VERSION ""

NS_ :

BS_:

BU_: BCU DGPS Debugger ECU InboardFloor_FL InboardFloor_FR InboardFloor_RL InboardFloor_RR SAMM_Mag_1 SuspensionNode_FL SuspensionNode_FR SuspensionNode_RL SuspensionNode_RR TCM TireTemp_FL TireTemp_FR TireTemp_RL TireTemp_RR

BO_ 2150629633 BCU_Debug_FD_to_Debugger: 64 BCU
 SG_ Debug : 0|64@1- (1,0) [0|0] "" Debugger

BO_ 2150629889 BCU_Ping_to_Debugger: 4 BCU
 SG_ Timestamp : 0|32@1+ (1,0) [0|4.29497e+09] "ms" Debugger

BO_ 2150629890 BCU_Ping_to_ECU: 4 BCU
 SG_ Timestamp : 0|32@1+ (1,0) [0|4.29497e+09] "ms" ECU

BO_ 2150632706 BCU_BCU_Cell_Data_1_to_ECU: 64 BCU
 SG_ Cell_0_Voltage : 0|8@1+ (0.01,2) [2|4.55] "Volts" ECU
 SG_ Cell_0_Temp : 8|8@1+ (0.25,0) [0|63.75] "Celsius" ECU
 SG_ Cell_1_Voltage : 16|8@1+ (0.01,2) [2|4.55] "Volts" ECU
 SG_ Cell_1_Temp : 24|8@1+ (0.25,0) [0|63.75] "Celsius" ECU
 SG_ Cell_2_Voltage : 32|8@1+ (0.01,2) [2|4.55] "Volts" ECU
 SG_ Cell_2_Temp : 40|8@1+ (0.25,0) [0|63.75] "Celsius" ECU
 SG_ Cell_3_Voltage : 48|8@1+ (0.01,2) [2|4.55] "Volts" ECU
 SG_ Cell_3_Temp : 56|8@1+ (0.25,0) [0|63.75] "Celsius" ECU
 SG_ Cell_4_Voltage : 64|8@1+ (0.01,2) [2|4.55] "Volts" ECU
 SG_ Cell_4_Temp : 72|8@1+ (0.25,0) [0|63.75] "Celsius" ECU
 SG_ Cell_5_Voltage : 80|8@1+ (0.01,2) [2|4.55] "Volts" ECU
 SG_ Cell_5_Temp : 88|8@1+ (0.25,0) [0|63.75] "Celsius" ECU
 SG_ Cell_6_Voltage : 96|8@1+ (0.01,2) [2|4.55] "Volts" ECU
 SG_ Cell_6_Temp : 104|8@1+ (0.25,0) [0|63.75] "Celsius" ECU
 SG_ Cell_7_Voltage : 112|8@1+ (0.01,2) [2|4.55] "Volts" ECU
 SG_ Cell_7_Temp : 120|8@1+ (0.25,0) [0|63.75] "Celsius" ECU
 SG_ Cell_8_Voltage : 128|8@1+ (0.01,2) [2|4.55] "Volts" ECU
 SG_ Cell_8_Temp : 136|8@1+ (0.25,0) [0|63.75] "Celsius" ECU
 SG_ Cell_9_Voltage : 144|8@1+ (0.01,2) [2|4.55] "Volts" ECU
 SG_ Cell_9_Temp : 152|8@1+ (0.25,0) [0|63.75] "Celsius" ECU
 SG_ Cell_10_Voltage : 160|8@1+ (0.01,2) [2|4.55] "Volts" ECU
 SG_ Cell_10_Temp : 168|8@1+ (0.25,0) [0|63.75] "Celsius" ECU
 SG_ Cell_11_Voltage : 176|8@1+ (0.01,2) [2|4.55] "Volts" ECU
 SG_ Cell_11_Temp : 184|8@1+ (0.25,0) [0|63.75] "Celsius" ECU
 SG_ Cell_12_Voltage : 192|8@1+ (0.01,2) [2|4.55] "Volts" ECU
 SG_ Cell_12_Temp : 200|8@1+ (0.25,0) [0|63.75] "Celsius" ECU
 SG_ Cell_13_Voltage : 208|8@1+ (0.01,2) [2|4.55] "Volts" ECU
 SG_ Cell_13_Temp : 216|8@1+ (0.25,0) [0|63.75] "Celsius" ECU
 SG_ Cell_14_Voltage : 224|8@1+ (0.01,2) [2|4.55] "Volts" ECU
 SG_ Cell_14_Temp : 232|8@1+ (0.25,0) [0|63.75] "Celsius" ECU
 SG_ Cell_15_Voltage : 240|8@1+ (0.01,2) [2|4.55] "Volts" ECU
 SG_ Cell_15_Temp : 248|8@1+ (0.25,0) [0|63.75] "Celsius" ECU
 SG_ Cell_16_Voltage : 256|8@1+ (0.01,2) [2|4.55] "Volts" ECU
 SG_ Cell_16_Temp : 264|8@1+ (0.25,0) [0|63.75] "Celsius" ECU
 SG_ Cell_17_Voltage : 272|8@1+ (0.01,2) [2|4.55] "Volts" ECU
 SG_ Cell_17_Temp : 280|8@1+ (0.25,0) [0|63.75] "Celsius" ECU
 SG_ Cell_18_Voltage : 288|8@1+ (0.01,2) [2|4.55] "Volts" ECU
 SG_ Cell_18_Temp : 296|8@1+ (0.25,0) [0|63.75] "Celsius" ECU
 SG_ Cell_19_Voltage : 304|8@1+ (0.01,2) [2|4.55] "Volts" ECU
 SG_ Cell_19_Temp : 312|8@1+ (0.25,0) [0|63.75] "Celsius" ECU
 SG_ Cell_20_Voltage : 320|8@1+ (0.01,2) [2|4.55] "Volts" ECU
 SG_ Cell_20_Temp : 328|8@1+ (0.25,0) [0|63.75] "Celsius" ECU
 SG_ Cell_21_Voltage : 336|8@1+ (0.01,2) [2|4.55] "Volts" ECU
 SG_ Cell_21_Temp : 344|8@1+ (0.25,0) [0|63.75] "Celsius" ECU
 SG_ Cell_22_Voltage : 352|8@1+ (0.01,2) [2|4.55] "Volts" ECU
 SG_ Cell_22_Temp : 360|8@1+ (0.25,0) [0|63.75] "Celsius" ECU
 SG_ Cell_23_Voltage : 368|8@1+ (0.01,2) [2|4.55] "Volts" ECU
 SG_ Cell_23_Temp : 376|8@1+ (0.25,0) [0|63.75] "Celsius" ECU
 SG_ Cell_24_Voltage : 384|8@1+ (0.01,2) [2|4.55] "Volts" ECU
 SG_ Cell_24_Temp : 392|8@1+ (0.25,0) [0|63.75] "Celsius" ECU
 SG_ Cell_25_Voltage : 400|8@1+ (0.01,2) [2|4.55] "Volts" ECU
 SG_ Cell_25_Temp : 408|8@1+ (0.25,0) [0|63.75] "Celsius" ECU
 SG_ Cell_26_Voltage : 416|8@1+ (0.01,2) [2|4.55] "Volts" ECU
 SG_ Cell_26_Temp : 424|8@1+ (0.25,0) [0|63.75] "Celsius" ECU
 SG_ Cell_27_Voltage : 432|8@1+ (0.01,2) [2|4.55] "Volts" ECU
 SG_ Cell_27_Temp : 440|8@1+ (0.25,0) [0|63.75] "Celsius" ECU
 SG_ Cell_28_Voltage : 448|8@1+ (0.01,2) [2|4.55] "Volts" ECU
 SG_ Cell_28_Temp : 456|8@1+ (0.25,0) [0|63.75] "Celsius" ECU
 SG_ Cell_29_Voltage : 464|8@1+ (0.01,2) [2|4.55] "Volts" ECU
 SG_ Cell_29_Temp : 472|8@1+ (0.25,0) [0|63.75] "Celsius" ECU
 SG_ Cell_30_Voltage : 480|8@1+ (0.01,2) [2|4.55] "Volts" ECU
 SG_ Cell_30_Temp : 488|8@1+ (0.25,0) [0|63.75] "Celsius" ECU
 SG_ Cell_31_Voltage : 496|8@1+ (0.01,2) [2|4.55] "Volts" ECU
 SG_ Cell_31_Temp : 504|8@1+ (0.25,0) [0|63.75] "Celsius" ECU

BO_ 2150632962 BCU_BCU_Cell_Data_2_to_ECU: 64 BCU
 SG_ Cell_32_Voltage : 0|8@1+ (0.01,2) [2|4.55] "Volts" ECU
 SG_ Cell_32_Temp : 8|8@1+ (0.25,0) [0|63.75] "Celsius" ECU
 SG_ Cell_33_Voltage : 16|8@1+ (0.01,2) [2|4.55] "Volts" ECU
 SG_ Cell_33_Temp : 24|8@1+ (0.25,0) [0|63.75] "Celsius" ECU
 SG_ Cell_34_Voltage : 32|8@1+ (0.01,2) [2|4.55] "Volts" ECU
 SG_ Cell_34_Temp : 40|8@1+ (0.25,0) [0|63.75] "Celsius" ECU
 SG_ Cell_35_Voltage : 48|8@1+ (0.01,2) [2|4.55] "Volts" ECU
 SG_ Cell_35_Temp : 56|8@1+ (0.25,0) [0|63.75] "Celsius" ECU
 SG_ Cell_36_Voltage : 64|8@1+ (0.01,2) [2|4.55] "Volts" ECU
 SG_ Cell_36_Temp : 72|8@1+ (0.25,0) [0|63.75] "Celsius" ECU
 SG_ Cell_37_Voltage : 80|8@1+ (0.01,2) [2|4.55] "Volts" ECU
 SG_ Cell_37_Temp : 88|8@1+ (0.25,0) [0|63.75] "Celsius" ECU
 SG_ Cell_38_Voltage : 96|8@1+ (0.01,2) [2|4.55] "Volts" ECU
 SG_ Cell_38_Temp : 104|8@1+ (0.25,0) [0|63.75] "Celsius" ECU
 SG_ Cell_39_Voltage : 112|8@1+ (0.01,2) [2|4.55] "Volts" ECU
 SG_ Cell_39_Temp : 120|8@1+ (0.25,0) [0|63.75] "Celsius" ECU
 SG_ Cell_40_Voltage : 128|8@1+ (0.01,2) [2|4.55] "Volts" ECU
 SG_ Cell_40_Temp : 136|8@1+ (0.25,0) [0|63.75] "Celsius" ECU
 SG_ Cell_41_Voltage : 144|8@1+ (0.01,2) [2|4.55] "Volts" ECU
 SG_ Cell_41_Temp : 152|8@1+ (0.25,0) [0|63.75] "Celsius" ECU
 SG_ Cell_42_Voltage : 160|8@1+ (0.01,2) [2|4.55] "Volts" ECU
 SG_ Cell_42_Temp : 168|8@1+ (0.25,0) [0|63.75] "Celsius" ECU
 SG_ Cell_43_Voltage : 176|8@1+ (0.01,2) [2|4.55] "Volts" ECU
 SG_ Cell_43_Temp : 184|8@1+ (0.25,0) [0|63.75] "Celsius" ECU
 SG_ Cell_44_Voltage : 192|8@1+ (0.01,2) [2|4.55] "Volts" ECU
 SG_ Cell_44_Temp : 200|8@1+ (0.25,0) [0|63.75] "Celsius" ECU
 SG_ Cell_45_Voltage : 208|8@1+ (0.01,2) [2|4.55] "Volts" ECU
 SG_ Cell_45_Temp : 216|8@1+ (0.25,0) [0|63.75] "Celsius" ECU
 SG_ Cell_46_Voltage : 224|8@1+ (0.01,2) [2|4.55] "Volts" ECU
 SG_ Cell_46_Temp : 232|8@1+ (0.25,0) [0|63.75] "Celsius" ECU
 SG_ Cell_47_Voltage : 240|8@1+ (0.01,2) [2|4.55] "Volts" ECU
 SG_ Cell_47_Temp : 248|8@1+ (0.25,0) [0|63.75] "Celsius" ECU
 SG_ Cell_48_Voltage : 256|8@1+ (0.01,2) [2|4.55] "Volts" ECU
 SG_ Cell_48_Temp : 264|8@1+ (0.25,0) [0|63.75] "Celsius" ECU
 SG_ Cell_49_Voltage : 272|8@1+ (0.01,2) [2|4.55] "Volts" ECU
 SG_ Cell_49_Temp : 280|8@1+ (0.25,0) [0|63.75] "Celsius" ECU
 SG_ Cell_50_Voltage : 288|8@1+ (0.01,2) [2|4.55] "Volts" ECU
 SG_ Cell_50_Temp : 296|8@1+ (0.25,0) [0|63.75] "Celsius" ECU
 SG_ Cell_51_Voltage : 304|8@1+ (0.01,2) [2|4.55] "Volts" ECU
 SG_ Cell_51_Temp : 312|8@1+ (0.25,0) [0|63.75] "Celsius" ECU
 SG_ Cell_52_Voltage : 320|8@1+ (0.01,2) [2|4.55] "Volts" ECU
 SG_ Cell_52_Temp : 328|8@1+ (0.25,0) [0|63.75] "Celsius" ECU
 SG_ Cell_53_Voltage : 336|8@1+ (0.01,2) [2|4.55] "Volts" ECU
 SG_ Cell_53_Temp : 344|8@1+ (0.25,0) [0|63.75] "Celsius" ECU
 SG_ Cell_54_Voltage : 352|8@1+ (0.01,2) [2|4.55] "Volts" ECU
 SG_ Cell_54_Temp : 360|8@1+ (0.25,0) [0|63.75] "Celsius" ECU
 SG_ Cell_55_Voltage : 368|8@1+ (0.01,2) [2|4.55] "Volts" ECU
 SG_ Cell_55_Temp : 376|8@1+ (0.25,0) [0|63.75] "Celsius" ECU
 SG_ Cell_56_Voltage : 384|8@1+ (0.01,2) [2|4.55] "Volts" ECU
 SG_ Cell_56_Temp : 392|8@1+ (0.25,0) [0|63.75] "Celsius" ECU
 SG_ Cell_57_Voltage : 400|8@1+ (0.01,2) [2|4.55] "Volts" ECU
 SG_ Cell_57_Temp : 408|8@1+ (0.25,0) [0|63.75] "Celsius" ECU
 SG_ Cell_58_Voltage : 416|8@1+ (0.01,2) [2|4.55] "Volts" ECU
 SG_ Cell_58_Temp : 424|8@1+ (0.25,0) [0|63.75] "Celsius" ECU
 SG_ Cell_59_Voltage : 432|8@1+ (0.01,2) [2|4.55] "Volts" ECU
 SG_ Cell_59_Temp : 440|8@1+ (0.25,0) [0|63.75] "Celsius" ECU
 SG_ Cell_60_Voltage : 448|8@1+ (0.01,2) [2|4.55] "Volts" ECU
 SG_ Cell_60_Temp : 456|8@1+ (0.25,0) [0|63.75] "Celsius" ECU
 SG_ Cell_61_Voltage : 464|8@1+ (0.01,2) [2|4.55] "Volts" ECU
 SG_ Cell_61_Temp : 472|8@1+ (0.25,0) [0|63.75] "Celsius" ECU
 SG_ Cell_62_Voltage : 480|8@1+ (0.01,2) [2|4.55] "Volts" ECU
 SG_ Cell_62_Temp : 488|8@1+ (0.25,0) [0|63.75] "Celsius" ECU
 SG_ Cell_63_Voltage : 496|8@1+ (0.01,2) [2|4.55] "Volts" ECU
 SG_ Cell_63_Temp : 504|8@1+ (0.25,0) [0|63.75] "Celsius" ECU

BO_ 2150633218 BCU_BCU_Cell_Data_3_to_ECU: 64 BCU
 SG_ Cell_64_Voltage : 0|8@1+ (0.01,2) [2|4.55] "Volts" ECU
 SG_ Cell_64_Temp : 8|8@1+ (0.25,0) [0|63.75] "Celsius" ECU
 SG_ Cell_65_Voltage : 16|8@1+ (0.01,2) [2|4.55] "Volts" ECU
 SG_ Cell_65_Temp : 24|8@1+ (0.25,0) [0|63.75] "Celsius" ECU
 SG_ Cell_66_Voltage : 32|8@1+ (0.01,2) [2|4.55] "Volts" ECU
 SG_ Cell_66_Temp : 40|8@1+ (0.25,0) [0|63.75] "Celsius" ECU
 SG_ Cell_67_Voltage : 48|8@1+ (0.01,2) [2|4.55] "Volts" ECU
 SG_ Cell_67_Temp : 56|8@1+ (0.25,0) [0|63.75] "Celsius" ECU
 SG_ Cell_68_Voltage : 64|8@1+ (0.01,2) [2|4.55] "Volts" ECU
 SG_ Cell_68_Temp : 72|8@1+ (0.25,0) [0|63.75] "Celsius" ECU
 SG_ Cell_69_Voltage : 80|8@1+ (0.01,2) [2|4.55] "Volts" ECU
 SG_ Cell_69_Temp : 88|8@1+ (0.25,0) [0|63.75] "Celsius" ECU
 SG_ Cell_70_Voltage : 96|8@1+ (0.01,2) [2|4.55] "Volts" ECU
 SG_ Cell_70_Temp : 104|8@1+ (0.25,0) [0|63.75] "Celsius" ECU
 SG_ Cell_71_Voltage : 112|8@1+ (0.01,2) [2|4.55] "Volts" ECU
 SG_ Cell_71_Temp : 120|8@1+ (0.25,0) [0|63.75] "Celsius" ECU
 SG_ Cell_72_Voltage : 128|8@1+ (0.01,2) [2|4.55] "Volts" ECU
 SG_ Cell_72_Temp : 136|8@1+ (0.25,0) [0|63.75] "Celsius" ECU
 SG_ Cell_73_Voltage : 144|8@1+ (0.01,2) [2|4.55] "Volts" ECU
 SG_ Cell_73_Temp : 152|8@1+ (0.25,0) [0|63.75] "Celsius" ECU
 SG_ Cell_74_Voltage : 160|8@1+ (0.01,2) [2|4.55] "Volts" ECU
 SG_ Cell_74_Temp : 168|8@1+ (0.25,0) [0|63.75] "Celsius" ECU
 SG_ Cell_75_Voltage : 176|8@1+ (0.01,2) [2|4.55] "Volts" ECU
 SG_ Cell_75_Temp : 184|8@1+ (0.25,0) [0|63.75] "Celsius" ECU
 SG_ Cell_76_Voltage : 192|8@1+ (0.01,2) [2|4.55] "Volts" ECU
 SG_ Cell_76_Temp : 200|8@1+ (0.25,0) [0|63.75] "Celsius" ECU
 SG_ Cell_77_Voltage : 208|8@1+ (0.01,2) [2|4.55] "Volts" ECU
 SG_ Cell_77_Temp : 216|8@1+ (0.25,0) [0|63.75] "Celsius" ECU
 SG_ Cell_78_Voltage : 224|8@1+ (0.01,2) [2|4.55] "Volts" ECU
 SG_ Cell_78_Temp : 232|8@1+ (0.25,0) [0|63.75] "Celsius" ECU
 SG_ Cell_79_Voltage : 240|8@1+ (0.01,2) [2|4.55] "Volts" ECU
 SG_ Cell_79_Temp : 248|8@1+ (0.25,0) [0|63.75] "Celsius" ECU
 SG_ Cell_80_Voltage : 256|8@1+ (0.01,2) [2|4.55] "Volts" ECU
 SG_ Cell_80_Temp : 264|8@1+ (0.25,0) [0|63.75] "Celsius" ECU
 SG_ Cell_81_Voltage : 272|8@1+ (0.01,2) [2|4.55] "Volts" ECU
 SG_ Cell_81_Temp : 280|8@1+ (0.25,0) [0|63.75] "Celsius" ECU
 SG_ Cell_82_Voltage : 288|8@1+ (0.01,2) [2|4.55] "Volts" ECU
 SG_ Cell_82_Temp : 296|8@1+ (0.25,0) [0|63.75] "Celsius" ECU
 SG_ Cell_83_Voltage : 304|8@1+ (0.01,2) [2|4.55] "Volts" ECU
 SG_ Cell_83_Temp : 312|8@1+ (0.25,0) [0|63.75] "Celsius" ECU
 SG_ Cell_84_Voltage : 320|8@1+ (0.01,2) [2|4.55] "Volts" ECU
 SG_ Cell_84_Temp : 328|8@1+ (0.25,0) [0|63.75] "Celsius" ECU
 SG_ Cell_85_Voltage : 336|8@1+ (0.01,2) [2|4.55] "Volts" ECU
 SG_ Cell_85_Temp : 344|8@1+ (0.25,0) [0|63.75] "Celsius" ECU
 SG_ Cell_86_Voltage : 352|8@1+ (0.01,2) [2|4.55] "Volts" ECU
 SG_ Cell_86_Temp : 360|8@1+ (0.25,0) [0|63.75] "Celsius" ECU
 SG_ Cell_87_Voltage : 368|8@1+ (0.01,2) [2|4.55] "Volts" ECU
 SG_ Cell_87_Temp : 376|8@1+ (0.25,0) [0|63.75] "Celsius" ECU
 SG_ Cell_88_Voltage : 384|8@1+ (0.01,2) [2|4.55] "Volts" ECU
 SG_ Cell_88_Temp : 392|8@1+ (0.25,0) [0|63.75] "Celsius" ECU
 SG_ Cell_89_Voltage : 400|8@1+ (0.01,2) [2|4.55] "Volts" ECU
 SG_ Cell_89_Temp : 408|8@1+ (0.25,0) [0|63.75] "Celsius" ECU
 SG_ Cell_90_Voltage : 416|8@1+ (0.01,2) [2|4.55] "Volts" ECU
 SG_ Cell_90_Temp : 424|8@1+ (0.25,0) [0|63.75] "Celsius" ECU
 SG_ Cell_91_Voltage : 432|8@1+ (0.01,2) [2|4.55] "Volts" ECU
 SG_ Cell_91_Temp : 440|8@1+ (0.25,0) [0|63.75] "Celsius" ECU
 SG_ Cell_92_Voltage : 448|8@1+ (0.01,2) [2|4.55] "Volts" ECU
 SG_ Cell_92_Temp : 456|8@1+ (0.25,0) [0|63.75] "Celsius" ECU
 SG_ Cell_93_Voltage : 464|8@1+ (0.01,2) [2|4.55] "Volts" ECU
 SG_ Cell_93_Temp : 472|8@1+ (0.25,0) [0|63.75] "Celsius" ECU
 SG_ Cell_94_Voltage : 480|8@1+ (0.01,2) [2|4.55] "Volts" ECU
 SG_ Cell_94_Temp : 488|8@1+ (0.25,0) [0|63.75] "Celsius" ECU
 SG_ Cell_95_Voltage : 496|8@1+ (0.01,2) [2|4.55] "Volts" ECU
 SG_ Cell_95_Temp : 504|8@1+ (0.25,0) [0|63.75] "Celsius" ECU

BO_ 2150633474 BCU_BCU_Cell_Data_4_to_ECU: 64 BCU
 SG_ Cell_96_Voltage : 0|8@1+ (0.01,2) [2|4.55] "Volts" ECU
 SG_ Cell_96_Temp : 8|8@1+ (0.25,0) [0|63.75] "Celsius" ECU
 SG_ Cell_97_Voltage : 16|8@1+ (0.01,2) [2|4.55] "Volts" ECU
 SG_ Cell_97_Temp : 24|8@1+ (0.25,0) [0|63.75] "Celsius" ECU
 SG_ Cell_98_Voltage : 32|8@1+ (0.01,2) [2|4.55] "Volts" ECU
 SG_ Cell_98_Temp : 40|8@1+ (0.25,0) [0|63.75] "Celsius" ECU
 SG_ Cell_99_Voltage : 48|8@1+ (0.01,2) [2|4.55] "Volts" ECU
 SG_ Cell_99_Temp : 56|8@1+ (0.25,0) [0|63.75] "Celsius" ECU
 SG_ Cell_100_Voltage : 64|8@1+ (0.01,2) [2|4.55] "Volts" ECU
 SG_ Cell_100_Temp : 72|8@1+ (0.25,0) [0|63.75] "Celsius" ECU
 SG_ Cell_101_Voltage : 80|8@1+ (0.01,2) [2|4.55] "Volts" ECU
 SG_ Cell_101_Temp : 88|8@1+ (0.25,0) [0|63.75] "Celsius" ECU
 SG_ Cell_102_Voltage : 96|8@1+ (0.01,2) [2|4.55] "Volts" ECU
 SG_ Cell_102_Temp : 104|8@1+ (0.25,0) [0|63.75] "Celsius" ECU
 SG_ Cell_103_Voltage : 112|8@1+ (0.01,2) [2|4.55] "Volts" ECU
 SG_ Cell_103_Temp : 120|8@1+ (0.25,0) [0|63.75] "Celsius" ECU
 SG_ Cell_104_Voltage : 128|8@1+ (0.01,2) [2|4.55] "Volts" ECU
 SG_ Cell_104_Temp : 136|8@1+ (0.25,0) [0|63.75] "Celsius" ECU
 SG_ Cell_105_Voltage : 144|8@1+ (0.01,2) [2|4.55] "Volts" ECU
 SG_ Cell_105_Temp : 152|8@1+ (0.25,0) [0|63.75] "Celsius" ECU
 SG_ Cell_106_Voltage : 160|8@1+ (0.01,2) [2|4.55] "Volts" ECU
 SG_ Cell_106_Temp : 168|8@1+ (0.25,0) [0|63.75] "Celsius" ECU
 SG_ Cell_107_Voltage : 176|8@1+ (0.01,2) [2|4.55] "Volts" ECU
 SG_ Cell_107_Temp : 184|8@1+ (0.25,0) [0|63.75] "Celsius" ECU
 SG_ Cell_108_Voltage : 192|8@1+ (0.01,2) [2|4.55] "Volts" ECU
 SG_ Cell_108_Temp : 200|8@1+ (0.25,0) [0|63.75] "Celsius" ECU
 SG_ Cell_109_Voltage : 208|8@1+ (0.01,2) [2|4.55] "Volts" ECU
 SG_ Cell_109_Temp : 216|8@1+ (0.25,0) [0|63.75] "Celsius" ECU
 SG_ Cell_110_Voltage : 224|8@1+ (0.01,2) [2|4.55] "Volts" ECU
 SG_ Cell_110_Temp : 232|8@1+ (0.25,0) [0|63.75] "Celsius" ECU
 SG_ Cell_111_Voltage : 240|8@1+ (0.01,2) [2|4.55] "Volts" ECU
 SG_ Cell_111_Temp : 248|8@1+ (0.25,0) [0|63.75] "Celsius" ECU
 SG_ Cell_112_Voltage : 256|8@1+ (0.01,2) [2|4.55] "Volts" ECU
 SG_ Cell_112_Temp : 264|8@1+ (0.25,0) [0|63.75] "Celsius" ECU
 SG_ Cell_113_Voltage : 272|8@1+ (0.01,2) [2|4.55] "Volts" ECU
 SG_ Cell_113_Temp : 280|8@1+ (0.25,0) [0|63.75] "Celsius" ECU
 SG_ Cell_114_Voltage : 288|8@1+ (0.01,2) [2|4.55] "Volts" ECU
 SG_ Cell_114_Temp : 296|8@1+ (0.25,0) [0|63.75] "Celsius" ECU
 SG_ Cell_115_Voltage : 304|8@1+ (0.01,2) [2|4.55] "Volts" ECU
 SG_ Cell_115_Temp : 312|8@1+ (0.25,0) [0|63.75] "Celsius" ECU
 SG_ Cell_116_Voltage : 320|8@1+ (0.01,2) [2|4.55] "Volts" ECU
 SG_ Cell_116_Temp : 328|8@1+ (0.25,0) [0|63.75] "Celsius" ECU
 SG_ Cell_117_Voltage : 336|8@1+ (0.01,2) [2|4.55] "Volts" ECU
 SG_ Cell_117_Temp : 344|8@1+ (0.25,0) [0|63.75] "Celsius" ECU
 SG_ Cell_118_Voltage : 352|8@1+ (0.01,2) [2|4.55] "Volts" ECU
 SG_ Cell_118_Temp : 360|8@1+ (0.25,0) [0|63.75] "Celsius" ECU
 SG_ Cell_119_Voltage : 368|8@1+ (0.01,2) [2|4.55] "Volts" ECU
 SG_ Cell_119_Temp : 376|8@1+ (0.25,0) [0|63.75] "Celsius" ECU
 SG_ Cell_120_Voltage : 384|8@1+ (0.01,2) [2|4.55] "Volts" ECU
 SG_ Cell_120_Temp : 392|8@1+ (0.25,0) [0|63.75] "Celsius" ECU
 SG_ Cell_121_Voltage : 400|8@1+ (0.01,2) [2|4.55] "Volts" ECU
 SG_ Cell_121_Temp : 408|8@1+ (0.25,0) [0|63.75] "Celsius" ECU
 SG_ Cell_122_Voltage : 416|8@1+ (0.01,2) [2|4.55] "Volts" ECU
 SG_ Cell_122_Temp : 424|8@1+ (0.25,0) [0|63.75] "Celsius" ECU
 SG_ Cell_123_Voltage : 432|8@1+ (0.01,2) [2|4.55] "Volts" ECU
 SG_ Cell_123_Temp : 440|8@1+ (0.25,0) [0|63.75] "Celsius" ECU
 SG_ Cell_124_Voltage : 448|8@1+ (0.01,2) [2|4.55] "Volts" ECU
 SG_ Cell_124_Temp : 456|8@1+ (0.25,0) [0|63.75] "Celsius" ECU
 SG_ Cell_125_Voltage : 464|8@1+ (0.01,2) [2|4.55] "Volts" ECU
 SG_ Cell_125_Temp : 472|8@1+ (0.25,0) [0|63.75] "Celsius" ECU
 SG_ Cell_126_Voltage : 480|8@1+ (0.01,2) [2|4.55] "Volts" ECU
 SG_ Cell_126_Temp : 488|8@1+ (0.25,0) [0|63.75] "Celsius" ECU
 SG_ Cell_127_Voltage : 496|8@1+ (0.01,2) [2|4.55] "Volts" ECU
 SG_ Cell_127_Temp : 504|8@1+ (0.25,0) [0|63.75] "Celsius" ECU

BO_ 2150633730 BCU_BCU_Cell_Data_5_to_ECU: 64 BCU
 SG_ Cell_128_Voltage : 0|8@1+ (0.01,2) [2|4.55] "Volts" ECU
 SG_ Cell_128_Temp : 8|8@1+ (0.25,0) [0|63.75] "Celsius" ECU
 SG_ Cell_129_Voltage : 16|8@1+ (0.01,2) [2|4.55] "Volts" ECU
 SG_ Cell_129_Temp : 24|8@1+ (0.25,0) [0|63.75] "Celsius" ECU
 SG_ Cell_130_Voltage : 32|8@1+ (0.01,2) [2|4.55] "Volts" ECU
 SG_ Cell_130_Temp : 40|8@1+ (0.25,0) [0|63.75] "Celsius" ECU
 SG_ Cell_131_Voltage : 48|8@1+ (0.01,2) [2|4.55] "Volts" ECU
 SG_ Cell_131_Temp : 56|8@1+ (0.25,0) [0|63.75] "Celsius" ECU
 SG_ Cell_132_Voltage : 64|8@1+ (0.01,2) [2|4.55] "Volts" ECU
 SG_ Cell_132_Temp : 72|8@1+ (0.25,0) [0|63.75] "Celsius" ECU
 SG_ Cell_133_Voltage : 80|8@1+ (0.01,2) [2|4.55] "Volts" ECU
 SG_ Cell_133_Temp : 88|8@1+ (0.25,0) [0|63.75] "Celsius" ECU
 SG_ Cell_134_Voltage : 96|8@1+ (0.01,2) [2|4.55] "Volts" ECU
 SG_ Cell_134_Temp : 104|8@1+ (0.25,0) [0|63.75] "Celsius" ECU
 SG_ Cell_135_Voltage : 112|8@1+ (0.01,2) [2|4.55] "Volts" ECU
 SG_ Cell_135_Temp : 120|8@1+ (0.25,0) [0|63.75] "Celsius" ECU
 SG_ Cell_136_Voltage : 128|8@1+ (0.01,2) [2|4.55] "Volts" ECU
 SG_ Cell_136_Temp : 136|8@1+ (0.25,0) [0|63.75] "Celsius" ECU
 SG_ Cell_137_Voltage : 144|8@1+ (0.01,2) [2|4.55] "Volts" ECU
 SG_ Cell_137_Temp : 152|8@1+ (0.25,0) [0|63.75] "Celsius" ECU
 SG_ Cell_138_Voltage : 160|8@1+ (0.01,2) [2|4.55] "Volts" ECU
 SG_ Cell_138_Temp : 168|8@1+ (0.25,0) [0|63.75] "Celsius" ECU
 SG_ Cell_139_Voltage : 176|8@1+ (0.01,2) [2|4.55] "Volts" ECU
 SG_ Cell_139_Temp : 184|8@1+ (0.25,0) [0|63.75] "Celsius" ECU
 SG_ Cell_140_Voltage : 192|8@1+ (0.01,2) [2|4.55] "Volts" ECU
 SG_ Cell_140_Temp : 200|8@1+ (0.25,0) [0|63.75] "Celsius" ECU
 SG_ Cell_141_Voltage : 208|8@1+ (0.01,2) [2|4.55] "Volts" ECU
 SG_ Cell_141_Temp : 216|8@1+ (0.25,0) [0|63.75] "Celsius" ECU
 SG_ Cell_142_Voltage : 224|8@1+ (0.01,2) [2|4.55] "Volts" ECU
 SG_ Cell_142_Temp : 232|8@1+ (0.25,0) [0|63.75] "Celsius" ECU
 SG_ Cell_143_Voltage : 240|8@1+ (0.01,2) [2|4.55] "Volts" ECU
 SG_ Cell_143_Temp : 248|8@1+ (0.25,0) [0|63.75] "Celsius" ECU
 SG_ Cell_144_Voltage : 256|8@1+ (0.01,2) [2|4.55] "Volts" ECU
 SG_ Cell_144_Temp : 264|8@1+ (0.25,0) [0|63.75] "Celsius" ECU
 SG_ Cell_145_Voltage : 272|8@1+ (0.01,2) [2|4.55] "Volts" ECU
 SG_ Cell_145_Temp : 280|8@1+ (0.25,0) [0|63.75] "Celsius" ECU
 SG_ Cell_146_Voltage : 288|8@1+ (0.01,2) [2|4.55] "Volts" ECU
 SG_ Cell_146_Temp : 296|8@1+ (0.25,0) [0|63.75] "Celsius" ECU
 SG_ Cell_147_Voltage : 304|8@1+ (0.01,2) [2|4.55] "Volts" ECU
 SG_ Cell_147_Temp : 312|8@1+ (0.25,0) [0|63.75] "Celsius" ECU
 SG_ Cell_148_Voltage : 320|8@1+ (0.01,2) [2|4.55] "Volts" ECU
 SG_ Cell_148_Temp : 328|8@1+ (0.25,0) [0|63.75] "Celsius" ECU
 SG_ Cell_149_Voltage : 336|8@1+ (0.01,2) [2|4.55] "Volts" ECU
 SG_ Cell_149_Temp : 344|8@1+ (0.25,0) [0|63.75] "Celsius" ECU
 SG_ Cell_150_Voltage : 352|8@1+ (0.01,2) [2|4.55] "Volts" ECU
 SG_ Cell_150_Temp : 360|8@1+ (0.25,0) [0|63.75] "Celsius" ECU
 SG_ Cell_151_Voltage : 368|8@1+ (0.01,2) [2|4.55] "Volts" ECU
 SG_ Cell_151_Temp : 376|8@1+ (0.25,0) [0|63.75] "Celsius" ECU
 SG_ Cell_152_Voltage : 384|8@1+ (0.01,2) [2|4.55] "Volts" ECU
 SG_ Cell_152_Temp : 392|8@1+ (0.25,0) [0|63.75] "Celsius" ECU
 SG_ Cell_153_Voltage : 400|8@1+ (0.01,2) [2|4.55] "Volts" ECU
 SG_ Cell_153_Temp : 408|8@1+ (0.25,0) [0|63.75] "Celsius" ECU
 SG_ Cell_154_Voltage : 416|8@1+ (0.01,2) [2|4.55] "Volts" ECU
 SG_ Cell_154_Temp : 424|8@1+ (0.25,0) [0|63.75] "Celsius" ECU
 SG_ Cell_155_Voltage : 432|8@1+ (0.01,2) [2|4.55] "Volts" ECU
 SG_ Cell_155_Temp : 440|8@1+ (0.25,0) [0|63.75] "Celsius" ECU
 SG_ Cell_156_Voltage : 448|8@1+ (0.01,2) [2|4.55] "Volts" ECU
 SG_ Cell_156_Temp : 456|8@1+ (0.25,0) [0|63.75] "Celsius" ECU
 SG_ Cell_157_Voltage : 464|8@1+ (0.01,2) [2|4.55] "Volts" ECU
 SG_ Cell_157_Temp : 472|8@1+ (0.25,0) [0|63.75] "Celsius" ECU
 SG_ Cell_158_Voltage : 480|8@1+ (0.01,2) [2|4.55] "Volts" ECU
 SG_ Cell_158_Temp : 488|8@1+ (0.25,0) [0|63.75] "Celsius" ECU
 SG_ Cell_159_Voltage : 496|8@1+ (0.01,2) [2|4.55] "Volts" ECU
 SG_ Cell_159_Temp : 504|8@1+ (0.25,0) [0|63.75] "Celsius" ECU

BO_ 2148532482 Debugger_Debug_FD_to_ECU: 64 Debugger
 SG_ Debug : 0|64@1- (1,0) [0|0] "" ECU

BO_ 2148532738 Debugger_Ping_to_ECU: 4 Debugger
 SG_ Timestamp : 0|32@1+ (1,0) [0|4.29497e+09] "ms" ECU

BO_ 2148532483 Debugger_Debug_FD_to_BCU: 64 Debugger
 SG_ Debug : 0|64@1- (1,0) [0|0] "" BCU

BO_ 2148532739 Debugger_Ping_to_BCU: 4 Debugger
 SG_ Timestamp : 0|32@1+ (1,0) [0|4.29497e+09] "ms" BCU

BO_ 2148532484 Debugger_Debug_FD_to_TCM: 64 Debugger
 SG_ Debug : 0|64@1- (1,0) [0|0] "" TCM

BO_ 2148532740 Debugger_Ping_to_TCM: 4 Debugger
 SG_ Timestamp : 0|32@1+ (1,0) [0|4.29497e+09] "ms" TCM

BO_ 2149581057 ECU_Debug_FD_to_Debugger: 64 ECU
 SG_ Debug : 0|64@1- (1,0) [0|0] "" Debugger

BO_ 2149581313 ECU_Ping_to_Debugger: 4 ECU
 SG_ Timestamp : 0|32@1+ (1,0) [0|4.29497e+09] "ms" Debugger

BO_ 2149592580 ECU_ECU_Analog_Data_to_TCM: 16 ECU
 SG_ BSPD_Signal : 0|16@1+ (0.0015259,0) [0|100] "%" TCM
 SG_ BSE_Signal : 16|16@1+ (0.0015259,0) [0|100] "%" TCM
 SG_ APPS_1_Signal : 32|16@1+ (0.0015259,0) [0|100] "%" TCM
 SG_ APPS_2_Signal : 48|16@1+ (0.0015259,0) [0|100] "%" TCM
 SG_ Brakeline_F_Signal : 64|16@1+ (0.0015259,0) [0|100] "%" TCM
 SG_ Brakeline_R_Signal : 80|16@1+ (0.0015259,0) [0|100] "%" TCM
 SG_ Steering_Angle_Signal : 96|16@1+ (0.0015259,0) [0|100] "%" TCM
 SG_ AUX_Signal : 112|16@1+ (0.0015259,0) [0|100] "%" TCM

BO_ 2149592836 ECU_ECU_Performance_to_TCM: 4 ECU
 SG_ Elapsed_Cycles : 0|32@1+ (1,0) [0|0] "Clock Cycles" TCM

BO_ 2147615264 ECU_Ping_to_InboardFloor_FL: 4 ECU
 SG_ Timestamp : 0|32@1+ (1,0) [0|4.29497e+09] "ms" InboardFloor_FL

BO_ 2147615265 ECU_Ping_to_InboardFloor_FR: 4 ECU
 SG_ Timestamp : 0|32@1+ (1,0) [0|4.29497e+09] "ms" InboardFloor_FR

BO_ 2147615266 ECU_Ping_to_InboardFloor_RL: 4 ECU
 SG_ Timestamp : 0|32@1+ (1,0) [0|4.29497e+09] "ms" InboardFloor_RL

BO_ 2147615267 ECU_Ping_to_InboardFloor_RR: 4 ECU
 SG_ Timestamp : 0|32@1+ (1,0) [0|4.29497e+09] "ms" InboardFloor_RR

BO_ 2147615268 ECU_Ping_to_SuspensionNode_FL: 4 ECU
 SG_ Timestamp : 0|32@1+ (1,0) [0|4.29497e+09] "ms" SuspensionNode_FL

BO_ 2147615269 ECU_Ping_to_SuspensionNode_FR: 4 ECU
 SG_ Timestamp : 0|32@1+ (1,0) [0|4.29497e+09] "ms" SuspensionNode_FR

BO_ 2147615270 ECU_Ping_to_SuspensionNode_RL: 4 ECU
 SG_ Timestamp : 0|32@1+ (1,0) [0|4.29497e+09] "ms" SuspensionNode_RL

BO_ 2147615271 ECU_Ping_to_SuspensionNode_RR: 4 ECU
 SG_ Timestamp : 0|32@1+ (1,0) [0|4.29497e+09] "ms" SuspensionNode_RR

BO_ 2151678465 TCM_Ping_to_Debugger: 4 TCM
 SG_ Timestamp : 0|32@1+ (1,0) [0|4.29497e+09] "ms" Debugger

BO_ 2197828356 DGPS_GPS_ALT_to_TCM: 8 DGPS
 SG_ ALT : 0|64@1+ (1,0) [0|0] "" TCM

BO_ 2197827844 DGPS_GPS_LAT_to_TCM: 8 DGPS
 SG_ LAT : 0|64@1+ (1,0) [0|0] "" TCM

BO_ 2197828100 DGPS_GPS_LON_to_TCM: 8 DGPS
 SG_ LON : 0|64@1+ (1,0) [0|0] "" TCM

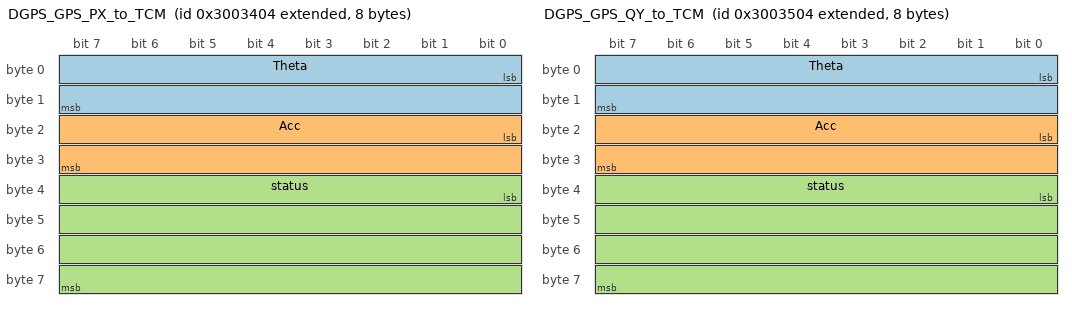
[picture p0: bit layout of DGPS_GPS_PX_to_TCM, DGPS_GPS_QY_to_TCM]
BO_ 2197828612 DGPS_GPS_PX_to_TCM: 8 DGPS
 SG_ Theta : 0|16@1- (0.001,0) [0|0] "" TCM
 SG_ Acc : 16|16@1- (0.01,0) [0|0] "" TCM
 SG_ status : 32|32@1+ (1,0) [0|0] "" TCM

BO_ 2197828868 DGPS_GPS_QY_to_TCM: 8 DGPS
 SG_ Theta : 0|16@1- (0.001,0) [0|0] "" TCM
 SG_ Acc : 16|16@1- (0.01,0) [0|0] "" TCM
 SG_ status : 32|32@1+ (1,0) [0|0] "" TCM

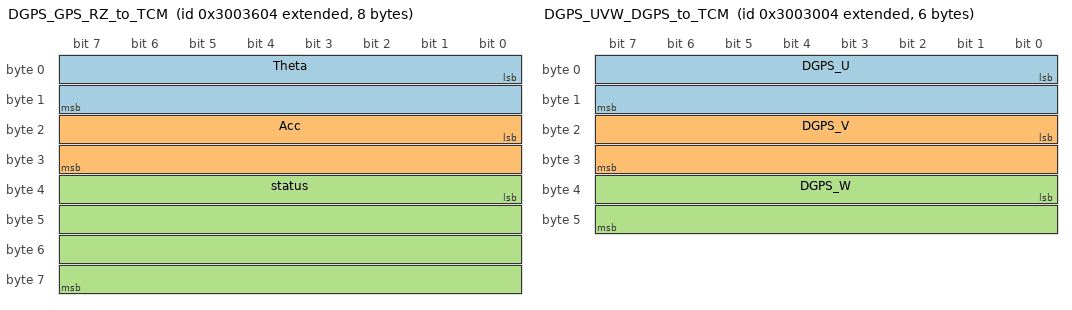
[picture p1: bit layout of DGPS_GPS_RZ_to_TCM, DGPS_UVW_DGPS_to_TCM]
BO_ 2197829124 DGPS_GPS_RZ_to_TCM: 8 DGPS
 SG_ Theta : 0|16@1- (0.001,0) [0|0] "" TCM
 SG_ Acc : 16|16@1- (0.01,0) [0|0] "" TCM
 SG_ status : 32|32@1+ (1,0) [0|0] "" TCM

BO_ 2197827588 DGPS_UVW_DGPS_to_TCM: 6 DGPS
 SG_ DGPS_U : 0|16@1- (0.01,0) [0|0] "" TCM
 SG_ DGPS_V : 16|16@1- (0.01,0) [0|0] "" TCM
 SG_ DGPS_W : 32|16@1- (0.01,0) [0|0] "" TCM

BO_ 514 SAMM_Mag_1_Ping_to_ECU: 4 SAMM_Mag_1
 SG_ Timestamp : 0|32@1+ (1,0) [0|4.29497e+09] "ms" ECU

BO_ 2150105602 TireTemp_FL_Ping_to_ECU: 4 TireTemp_FL
 SG_ Timestamp : 0|32@1+ (1,0) [0|4.29497e+09] "ms" ECU

BO_ 2150171138 TireTemp_FR_Ping_to_ECU: 4 TireTemp_FR
 SG_ Timestamp : 0|32@1+ (1,0) [0|4.29497e+09] "ms" ECU

BO_ 2150236674 TireTemp_RL_Ping_to_ECU: 4 TireTemp_RL
 SG_ Timestamp : 0|32@1+ (1,0) [0|4.29497e+09] "ms" ECU

BO_ 2150302210 TireTemp_RR_Ping_to_ECU: 4 TireTemp_RR
 SG_ Timestamp : 0|32@1+ (1,0) [0|4.29497e+09] "ms" ECU

CM_ SG_ 2147680513 Debug "Essentially a print statement up to 64 bytes long that whichever targeted can parse";
CM_ SG_ 2147680769 Timestamp "Time in millis";
CM_ SG_ 2147680770 Timestamp "Time in millis";
CM_ SG_ 2147683586 Cell_0_Voltage "Cell  n voltage";
CM_ SG_ 2147683586 Cell_0_Temp "Cell n temperature";
CM_ SG_ 2147683586 Cell_1_Voltage "Cell  n voltage";
CM_ SG_ 2147683586 Cell_1_Temp "Cell n temperature";
CM_ SG_ 2147683586 Cell_2_Voltage "Cell  n voltage";
CM_ SG_ 2147683586 Cell_2_Temp "Cell n temperature";
CM_ SG_ 2147683586 Cell_3_Voltage "Cell  n voltage";
CM_ SG_ 2147683586 Cell_3_Temp "Cell n temperature";
CM_ SG_ 2147683586 Cell_4_Voltage "Cell  n voltage";
CM_ SG_ 2147683586 Cell_4_Temp "Cell n temperature";
CM_ SG_ 2147683586 Cell_5_Voltage "Cell  n voltage";
CM_ SG_ 2147683586 Cell_5_Temp "Cell n temperature";
CM_ SG_ 2147683586 Cell_6_Voltage "Cell  n voltage";
CM_ SG_ 2147683586 Cell_6_Temp "Cell n temperature";
CM_ SG_ 2147683586 Cell_7_Voltage "Cell  n voltage";
CM_ SG_ 2147683586 Cell_7_Temp "Cell n temperature";
CM_ SG_ 2147683586 Cell_8_Voltage "Cell  n voltage";
CM_ SG_ 2147683586 Cell_8_Temp "Cell n temperature";
CM_ SG_ 2147683586 Cell_9_Voltage "Cell  n voltage";
CM_ SG_ 2147683586 Cell_9_Temp "Cell n temperature";
CM_ SG_ 2147683586 Cell_10_Voltage "Cell  n voltage";
CM_ SG_ 2147683586 Cell_10_Temp "Cell n temperature";
CM_ SG_ 2147683586 Cell_11_Voltage "Cell  n voltage";
CM_ SG_ 2147683586 Cell_11_Temp "Cell n temperature";
CM_ SG_ 2147683586 Cell_12_Voltage "Cell  n voltage";
CM_ SG_ 2147683586 Cell_12_Temp "Cell n temperature";
CM_ SG_ 2147683586 Cell_13_Voltage "Cell  n voltage";
CM_ SG_ 2147683586 Cell_13_Temp "Cell n temperature";
CM_ SG_ 2147683586 Cell_14_Voltage "Cell  n voltage";
CM_ SG_ 2147683586 Cell_14_Temp "Cell n temperature";
CM_ SG_ 2147683586 Cell_15_Voltage "Cell  n voltage";
CM_ SG_ 2147683586 Cell_15_Temp "Cell n temperature";
CM_ SG_ 2147683586 Cell_16_Voltage "Cell  n voltage";
CM_ SG_ 2147683586 Cell_16_Temp "Cell n temperature";
CM_ SG_ 2147683586 Cell_17_Voltage "Cell  n voltage";
CM_ SG_ 2147683586 Cell_17_Temp "Cell n temperature";
CM_ SG_ 2147683586 Cell_18_Voltage "Cell  n voltage";
CM_ SG_ 2147683586 Cell_18_Temp "Cell n temperature";
CM_ SG_ 2147683586 Cell_19_Voltage "Cell  n voltage";
CM_ SG_ 2147683586 Cell_19_Temp "Cell n temperature";
CM_ SG_ 2147683586 Cell_20_Voltage "Cell  n voltage";
CM_ SG_ 2147683586 Cell_20_Temp "Cell n temperature";
CM_ SG_ 2147683586 Cell_21_Voltage "Cell  n voltage";
CM_ SG_ 2147683586 Cell_21_Temp "Cell n temperature";
CM_ SG_ 2147683586 Cell_22_Voltage "Cell  n voltage";
CM_ SG_ 2147683586 Cell_22_Temp "Cell n temperature";
CM_ SG_ 2147683586 Cell_23_Voltage "Cell  n voltage";
CM_ SG_ 2147683586 Cell_23_Temp "Cell n temperature";
CM_ SG_ 2147683586 Cell_24_Voltage "Cell  n voltage";
CM_ SG_ 2147683586 Cell_24_Temp "Cell n temperature";
CM_ SG_ 2147683586 Cell_25_Voltage "Cell  n voltage";
CM_ SG_ 2147683586 Cell_25_Temp "Cell n temperature";
CM_ SG_ 2147683586 Cell_26_Voltage "Cell  n voltage";
CM_ SG_ 2147683586 Cell_26_Temp "Cell n temperature";
CM_ SG_ 2147683586 Cell_27_Voltage "Cell  n voltage";
CM_ SG_ 2147683586 Cell_27_Temp "Cell n temperature";
CM_ SG_ 2147683586 Cell_28_Voltage "Cell  n voltage";
CM_ SG_ 2147683586 Cell_28_Temp "Cell n temperature";
CM_ SG_ 2147683586 Cell_29_Voltage "Cell  n voltage";
CM_ SG_ 2147683586 Cell_29_Temp "Cell n temperature";
CM_ SG_ 2147683586 Cell_30_Voltage "Cell  n voltage";
CM_ SG_ 2147683586 Cell_30_Temp "Cell n temperature";
CM_ SG_ 2147683586 Cell_31_Voltage "Cell  n voltage";
CM_ SG_ 2147683586 Cell_31_Temp "Cell n temperature";
CM_ SG_ 2147683842 Cell_32_Voltage "Cell  n voltage";
CM_ SG_ 2147683842 Cell_32_Temp "Cell n temperature";
CM_ SG_ 2147683842 Cell_33_Voltage "Cell  n voltage";
CM_ SG_ 2147683842 Cell_33_Temp "Cell n temperature";
CM_ SG_ 2147683842 Cell_34_Voltage "Cell  n voltage";
CM_ SG_ 2147683842 Cell_34_Temp "Cell n temperature";
CM_ SG_ 2147683842 Cell_35_Voltage "Cell  n voltage";
CM_ SG_ 2147683842 Cell_35_Temp "Cell n temperature";
CM_ SG_ 2147683842 Cell_36_Voltage "Cell  n voltage";
CM_ SG_ 2147683842 Cell_36_Temp "Cell n temperature";
CM_ SG_ 2147683842 Cell_37_Voltage "Cell  n voltage";
CM_ SG_ 2147683842 Cell_37_Temp "Cell n temperature";
CM_ SG_ 2147683842 Cell_38_Voltage "Cell  n voltage";
CM_ SG_ 2147683842 Cell_38_Temp "Cell n temperature";
CM_ SG_ 2147683842 Cell_39_Voltage "Cell  n voltage";
CM_ SG_ 2147683842 Cell_39_Temp "Cell n temperature";
CM_ SG_ 2147683842 Cell_40_Voltage "Cell  n voltage";
CM_ SG_ 2147683842 Cell_40_Temp "Cell n temperature";
CM_ SG_ 2147683842 Cell_41_Voltage "Cell  n voltage";
CM_ SG_ 2147683842 Cell_41_Temp "Cell n temperature";
CM_ SG_ 2147683842 Cell_42_Voltage "Cell  n voltage";
CM_ SG_ 2147683842 Cell_42_Temp "Cell n temperature";
CM_ SG_ 2147683842 Cell_43_Voltage "Cell  n voltage";
CM_ SG_ 2147683842 Cell_43_Temp "Cell n temperature";
CM_ SG_ 2147683842 Cell_44_Voltage "Cell  n voltage";
CM_ SG_ 2147683842 Cell_44_Temp "Cell n temperature";
CM_ SG_ 2147683842 Cell_45_Voltage "Cell  n voltage";
CM_ SG_ 2147683842 Cell_45_Temp "Cell n temperature";
CM_ SG_ 2147683842 Cell_46_Voltage "Cell  n voltage";
CM_ SG_ 2147683842 Cell_46_Temp "Cell n temperature";
CM_ SG_ 2147683842 Cell_47_Voltage "Cell  n voltage";
CM_ SG_ 2147683842 Cell_47_Temp "Cell n temperature";
CM_ SG_ 2147683842 Cell_48_Voltage "Cell  n voltage";
CM_ SG_ 2147683842 Cell_48_Temp "Cell n temperature";
CM_ SG_ 2147683842 Cell_49_Voltage "Cell  n voltage";
CM_ SG_ 2147683842 Cell_49_Temp "Cell n temperature";
CM_ SG_ 2147683842 Cell_50_Voltage "Cell  n voltage";
CM_ SG_ 2147683842 Cell_50_Temp "Cell n temperature";
CM_ SG_ 2147683842 Cell_51_Voltage "Cell  n voltage";
CM_ SG_ 2147683842 Cell_51_Temp "Cell n temperature";
CM_ SG_ 2147683842 Cell_52_Voltage "Cell  n voltage";
CM_ SG_ 2147683842 Cell_52_Temp "Cell n temperature";
CM_ SG_ 2147683842 Cell_53_Voltage "Cell  n voltage";
CM_ SG_ 2147683842 Cell_53_Temp "Cell n temperature";
CM_ SG_ 2147683842 Cell_54_Voltage "Cell  n voltage";
CM_ SG_ 2147683842 Cell_54_Temp "Cell n temperature";
CM_ SG_ 2147683842 Cell_55_Voltage "Cell  n voltage";
CM_ SG_ 2147683842 Cell_55_Temp "Cell n temperature";
CM_ SG_ 2147683842 Cell_56_Voltage "Cell  n voltage";
CM_ SG_ 2147683842 Cell_56_Temp "Cell n temperature";
CM_ SG_ 2147683842 Cell_57_Voltage "Cell  n voltage";
CM_ SG_ 2147683842 Cell_57_Temp "Cell n temperature";
CM_ SG_ 2147683842 Cell_58_Voltage "Cell  n voltage";
CM_ SG_ 2147683842 Cell_58_Temp "Cell n temperature";
CM_ SG_ 2147683842 Cell_59_Voltage "Cell  n voltage";
CM_ SG_ 2147683842 Cell_59_Temp "Cell n temperature";
CM_ SG_ 2147683842 Cell_60_Voltage "Cell  n voltage";
CM_ SG_ 2147683842 Cell_60_Temp "Cell n temperature";
CM_ SG_ 2147683842 Cell_61_Voltage "Cell  n voltage";
CM_ SG_ 2147683842 Cell_61_Temp "Cell n temperature";
CM_ SG_ 2147683842 Cell_62_Voltage "Cell  n voltage";
CM_ SG_ 2147683842 Cell_62_Temp "Cell n temperature";
CM_ SG_ 2147683842 Cell_63_Voltage "Cell  n voltage";
CM_ SG_ 2147683842 Cell_63_Temp "Cell n temperature";
CM_ SG_ 2147684098 Cell_64_Voltage "Cell  n voltage";
CM_ SG_ 2147684098 Cell_64_Temp "Cell n temperature";
CM_ SG_ 2147684098 Cell_65_Voltage "Cell  n voltage";
CM_ SG_ 2147684098 Cell_65_Temp "Cell n temperature";
CM_ SG_ 2147684098 Cell_66_Voltage "Cell  n voltage";
CM_ SG_ 2147684098 Cell_66_Temp "Cell n temperature";
CM_ SG_ 2147684098 Cell_67_Voltage "Cell  n voltage";
CM_ SG_ 2147684098 Cell_67_Temp "Cell n temperature";
CM_ SG_ 2147684098 Cell_68_Voltage "Cell  n voltage";
CM_ SG_ 2147684098 Cell_68_Temp "Cell n temperature";
CM_ SG_ 2147684098 Cell_69_Voltage "Cell  n voltage";
CM_ SG_ 2147684098 Cell_69_Temp "Cell n temperature";
CM_ SG_ 2147684098 Cell_70_Voltage "Cell  n voltage";
CM_ SG_ 2147684098 Cell_70_Temp "Cell n temperature";
CM_ SG_ 2147684098 Cell_71_Voltage "Cell  n voltage";
CM_ SG_ 2147684098 Cell_71_Temp "Cell n temperature";
CM_ SG_ 2147684098 Cell_72_Voltage "Cell  n voltage";
CM_ SG_ 2147684098 Cell_72_Temp "Cell n temperature";
CM_ SG_ 2147684098 Cell_73_Voltage "Cell  n voltage";
CM_ SG_ 2147684098 Cell_73_Temp "Cell n temperature";
CM_ SG_ 2147684098 Cell_74_Voltage "Cell  n voltage";
CM_ SG_ 2147684098 Cell_74_Temp "Cell n temperature";
CM_ SG_ 2147684098 Cell_75_Voltage "Cell  n voltage";
CM_ SG_ 2147684098 Cell_75_Temp "Cell n temperature";
CM_ SG_ 2147684098 Cell_76_Voltage "Cell  n voltage";
CM_ SG_ 2147684098 Cell_76_Temp "Cell n temperature";
CM_ SG_ 2147684098 Cell_77_Voltage "Cell  n voltage";
CM_ SG_ 2147684098 Cell_77_Temp "Cell n temperature";
CM_ SG_ 2147684098 Cell_78_Voltage "Cell  n voltage";
CM_ SG_ 2147684098 Cell_78_Temp "Cell n temperature";
CM_ SG_ 2147684098 Cell_79_Voltage "Cell  n voltage";
CM_ SG_ 2147684098 Cell_79_Temp "Cell n temperature";
CM_ SG_ 2147684098 Cell_80_Voltage "Cell  n voltage";
CM_ SG_ 2147684098 Cell_80_Temp "Cell n temperature";
CM_ SG_ 2147684098 Cell_81_Voltage "Cell  n voltage";
CM_ SG_ 2147684098 Cell_81_Temp "Cell n temperature";
CM_ SG_ 2147684098 Cell_82_Voltage "Cell  n voltage";
CM_ SG_ 2147684098 Cell_82_Temp "Cell n temperature";
CM_ SG_ 2147684098 Cell_83_Voltage "Cell  n voltage";
CM_ SG_ 2147684098 Cell_83_Temp "Cell n temperature";
CM_ SG_ 2147684098 Cell_84_Voltage "Cell  n voltage";
CM_ SG_ 2147684098 Cell_84_Temp "Cell n temperature";
CM_ SG_ 2147684098 Cell_85_Voltage "Cell  n voltage";
CM_ SG_ 2147684098 Cell_85_Temp "Cell n temperature";
CM_ SG_ 2147684098 Cell_86_Voltage "Cell  n voltage";
CM_ SG_ 2147684098 Cell_86_Temp "Cell n temperature";
CM_ SG_ 2147684098 Cell_87_Voltage "Cell  n voltage";
CM_ SG_ 2147684098 Cell_87_Temp "Cell n temperature";
CM_ SG_ 2147684098 Cell_88_Voltage "Cell  n voltage";
CM_ SG_ 2147684098 Cell_88_Temp "Cell n temperature";
CM_ SG_ 2147684098 Cell_89_Voltage "Cell  n voltage";
CM_ SG_ 2147684098 Cell_89_Temp "Cell n temperature";
CM_ SG_ 2147684098 Cell_90_Voltage "Cell  n voltage";
CM_ SG_ 2147684098 Cell_90_Temp "Cell n temperature";
CM_ SG_ 2147684098 Cell_91_Voltage "Cell  n voltage";
CM_ SG_ 2147684098 Cell_91_Temp "Cell n temperature";
CM_ SG_ 2147684098 Cell_92_Voltage "Cell  n voltage";
CM_ SG_ 2147684098 Cell_92_Temp "Cell n temperature";
CM_ SG_ 2147684098 Cell_93_Voltage "Cell  n voltage";
CM_ SG_ 2147684098 Cell_93_Temp "Cell n temperature";
CM_ SG_ 2147684098 Cell_94_Voltage "Cell  n voltage";
CM_ SG_ 2147684098 Cell_94_Temp "Cell n temperature";
CM_ SG_ 2147684098 Cell_95_Voltage "Cell  n voltage";
CM_ SG_ 2147684098 Cell_95_Temp "Cell n temperature";
CM_ SG_ 2147684354 Cell_96_Voltage "Cell  n voltage";
CM_ SG_ 2147684354 Cell_96_Temp "Cell n temperature";
CM_ SG_ 2147684354 Cell_97_Voltage "Cell  n voltage";
CM_ SG_ 2147684354 Cell_97_Temp "Cell n temperature";
CM_ SG_ 2147684354 Cell_98_Voltage "Cell  n voltage";
CM_ SG_ 2147684354 Cell_98_Temp "Cell n temperature";
CM_ SG_ 2147684354 Cell_99_Voltage "Cell  n voltage";
CM_ SG_ 2147684354 Cell_99_Temp "Cell n temperature";
CM_ SG_ 2147684354 Cell_100_Voltage "Cell  n voltage";
CM_ SG_ 2147684354 Cell_100_Temp "Cell n temperature";
CM_ SG_ 2147684354 Cell_101_Voltage "Cell  n voltage";
CM_ SG_ 2147684354 Cell_101_Temp "Cell n temperature";
CM_ SG_ 2147684354 Cell_102_Voltage "Cell  n voltage";
CM_ SG_ 2147684354 Cell_102_Temp "Cell n temperature";
CM_ SG_ 2147684354 Cell_103_Voltage "Cell  n voltage";
CM_ SG_ 2147684354 Cell_103_Temp "Cell n temperature";
CM_ SG_ 2147684354 Cell_104_Voltage "Cell  n voltage";
CM_ SG_ 2147684354 Cell_104_Temp "Cell n temperature";
CM_ SG_ 2147684354 Cell_105_Voltage "Cell  n voltage";
CM_ SG_ 2147684354 Cell_105_Temp "Cell n temperature";
CM_ SG_ 2147684354 Cell_106_Voltage "Cell  n voltage";
CM_ SG_ 2147684354 Cell_106_Temp "Cell n temperature";
CM_ SG_ 2147684354 Cell_107_Voltage "Cell  n voltage";
CM_ SG_ 2147684354 Cell_107_Temp "Cell n temperature";
CM_ SG_ 2147684354 Cell_108_Voltage "Cell  n voltage";
CM_ SG_ 2147684354 Cell_108_Temp "Cell n temperature";
CM_ SG_ 2147684354 Cell_109_Voltage "Cell  n voltage";
CM_ SG_ 2147684354 Cell_109_Temp "Cell n temperature";
CM_ SG_ 2147684354 Cell_110_Voltage "Cell  n voltage";
CM_ SG_ 2147684354 Cell_110_Temp "Cell n temperature";
CM_ SG_ 2147684354 Cell_111_Voltage "Cell  n voltage";
CM_ SG_ 2147684354 Cell_111_Temp "Cell n temperature";
CM_ SG_ 2147684354 Cell_112_Voltage "Cell  n voltage";
CM_ SG_ 2147684354 Cell_112_Temp "Cell n temperature";
CM_ SG_ 2147684354 Cell_113_Voltage "Cell  n voltage";
CM_ SG_ 2147684354 Cell_113_Temp "Cell n temperature";
CM_ SG_ 2147684354 Cell_114_Voltage "Cell  n voltage";
CM_ SG_ 2147684354 Cell_114_Temp "Cell n temperature";
CM_ SG_ 2147684354 Cell_115_Voltage "Cell  n voltage";
CM_ SG_ 2147684354 Cell_115_Temp "Cell n temperature";
CM_ SG_ 2147684354 Cell_116_Voltage "Cell  n voltage";
CM_ SG_ 2147684354 Cell_116_Temp "Cell n temperature";
CM_ SG_ 2147684354 Cell_117_Voltage "Cell  n voltage";
CM_ SG_ 2147684354 Cell_117_Temp "Cell n temperature";
CM_ SG_ 2147684354 Cell_118_Voltage "Cell  n voltage";
CM_ SG_ 2147684354 Cell_118_Temp "Cell n temperature";
CM_ SG_ 2147684354 Cell_119_Voltage "Cell  n voltage";
CM_ SG_ 2147684354 Cell_119_Temp "Cell n temperature";
CM_ SG_ 2147684354 Cell_120_Voltage "Cell  n voltage";
CM_ SG_ 2147684354 Cell_120_Temp "Cell n temperature";
CM_ SG_ 2147684354 Cell_121_Voltage "Cell  n voltage";
CM_ SG_ 2147684354 Cell_121_Temp "Cell n temperature";
CM_ SG_ 2147684354 Cell_122_Voltage "Cell  n voltage";
CM_ SG_ 2147684354 Cell_122_Temp "Cell n temperature";
CM_ SG_ 2147684354 Cell_123_Voltage "Cell  n voltage";
CM_ SG_ 2147684354 Cell_123_Temp "Cell n temperature";
CM_ SG_ 2147684354 Cell_124_Voltage "Cell  n voltage";
CM_ SG_ 2147684354 Cell_124_Temp "Cell n temperature";
CM_ SG_ 2147684354 Cell_125_Voltage "Cell  n voltage";
CM_ SG_ 2147684354 Cell_125_Temp "Cell n temperature";
CM_ SG_ 2147684354 Cell_126_Voltage "Cell  n voltage";
CM_ SG_ 2147684354 Cell_126_Temp "Cell n temperature";
CM_ SG_ 2147684354 Cell_127_Voltage "Cell  n voltage";
CM_ SG_ 2147684354 Cell_127_Temp "Cell n temperature";
CM_ SG_ 2147684610 Cell_128_Voltage "Cell  n voltage";
CM_ SG_ 2147684610 Cell_128_Temp "Cell n temperature";
CM_ SG_ 2147684610 Cell_129_Voltage "Cell  n voltage";
CM_ SG_ 2147684610 Cell_129_Temp "Cell n temperature";
CM_ SG_ 2147684610 Cell_130_Voltage "Cell  n voltage";
CM_ SG_ 2147684610 Cell_130_Temp "Cell n temperature";
CM_ SG_ 2147684610 Cell_131_Voltage "Cell  n voltage";
CM_ SG_ 2147684610 Cell_131_Temp "Cell n temperature";
CM_ SG_ 2147684610 Cell_132_Voltage "Cell  n voltage";
CM_ SG_ 2147684610 Cell_132_Temp "Cell n temperature";
CM_ SG_ 2147684610 Cell_133_Voltage "Cell  n voltage";
CM_ SG_ 2147684610 Cell_133_Temp "Cell n temperature";
CM_ SG_ 2147684610 Cell_134_Voltage "Cell  n voltage";
CM_ SG_ 2147684610 Cell_134_Temp "Cell n temperature";
CM_ SG_ 2147684610 Cell_135_Voltage "Cell  n voltage";
CM_ SG_ 2147684610 Cell_135_Temp "Cell n temperature";
CM_ SG_ 2147684610 Cell_136_Voltage "Cell  n voltage";
CM_ SG_ 2147684610 Cell_136_Temp "Cell n temperature";
CM_ SG_ 2147684610 Cell_137_Voltage "Cell  n voltage";
CM_ SG_ 2147684610 Cell_137_Temp "Cell n temperature";
CM_ SG_ 2147684610 Cell_138_Voltage "Cell  n voltage";
CM_ SG_ 2147684610 Cell_138_Temp "Cell n temperature";
CM_ SG_ 2147684610 Cell_139_Voltage "Cell  n voltage";
CM_ SG_ 2147684610 Cell_139_Temp "Cell n temperature";
CM_ SG_ 2147684610 Cell_140_Voltage "Cell  n voltage";
CM_ SG_ 2147684610 Cell_140_Temp "Cell n temperature";
CM_ SG_ 2147684610 Cell_141_Voltage "Cell  n voltage";
CM_ SG_ 2147684610 Cell_141_Temp "Cell n temperature";
CM_ SG_ 2147684610 Cell_142_Voltage "Cell  n voltage";
CM_ SG_ 2147684610 Cell_142_Temp "Cell n temperature";
CM_ SG_ 2147684610 Cell_143_Voltage "Cell  n voltage";
CM_ SG_ 2147684610 Cell_143_Temp "Cell n temperature";
CM_ SG_ 2147684610 Cell_144_Voltage "Cell  n voltage";
CM_ SG_ 2147684610 Cell_144_Temp "Cell n temperature";
CM_ SG_ 2147684610 Cell_145_Voltage "Cell  n voltage";
CM_ SG_ 2147684610 Cell_145_Temp "Cell n temperature";
CM_ SG_ 2147684610 Cell_146_Voltage "Cell  n voltage";
CM_ SG_ 2147684610 Cell_146_Temp "Cell n temperature";
CM_ SG_ 2147684610 Cell_147_Voltage "Cell  n voltage";
CM_ SG_ 2147684610 Cell_147_Temp "Cell n temperature";
CM_ SG_ 2147684610 Cell_148_Voltage "Cell  n voltage";
CM_ SG_ 2147684610 Cell_148_Temp "Cell n temperature";
CM_ SG_ 2147684610 Cell_149_Voltage "Cell  n voltage";
CM_ SG_ 2147684610 Cell_149_Temp "Cell n temperature";
CM_ SG_ 2147684610 Cell_150_Voltage "Cell  n voltage";
CM_ SG_ 2147684610 Cell_150_Temp "Cell n temperature";
CM_ SG_ 2147684610 Cell_151_Voltage "Cell  n voltage";
CM_ SG_ 2147684610 Cell_151_Temp "Cell n temperature";
CM_ SG_ 2147684610 Cell_152_Voltage "Cell  n voltage";
CM_ SG_ 2147684610 Cell_152_Temp "Cell n temperature";
CM_ SG_ 2147684610 Cell_153_Voltage "Cell  n voltage";
CM_ SG_ 2147684610 Cell_153_Temp "Cell n temperature";
CM_ SG_ 2147684610 Cell_154_Voltage "Cell  n voltage";
CM_ SG_ 2147684610 Cell_154_Temp "Cell n temperature";
CM_ SG_ 2147684610 Cell_155_Voltage "Cell  n voltage";
CM_ SG_ 2147684610 Cell_155_Temp "Cell n temperature";
CM_ SG_ 2147684610 Cell_156_Voltage "Cell  n voltage";
CM_ SG_ 2147684610 Cell_156_Temp "Cell n temperature";
CM_ SG_ 2147684610 Cell_157_Voltage "Cell  n voltage";
CM_ SG_ 2147684610 Cell_157_Temp "Cell n temperature";
CM_ SG_ 2147684610 Cell_158_Voltage "Cell  n voltage";
CM_ SG_ 2147684610 Cell_158_Temp "Cell n temperature";
CM_ SG_ 2147684610 Cell_159_Voltage "Cell  n voltage";
CM_ SG_ 2147684610 Cell_159_Temp "Cell n temperature";
CM_ SG_ 2147549442 Debug "Essentially a print statement up to 64 bytes long that whichever targeted can parse";
CM_ SG_ 2147549698 Timestamp "Time in millis";
CM_ SG_ 2147549443 Debug "Essentially a print statement up to 64 bytes long that whichever targeted can parse";
CM_ SG_ 2147549699 Timestamp "Time in millis";
CM_ SG_ 2147549444 Debug "Essentially a print statement up to 64 bytes long that whichever targeted can parse";
CM_ SG_ 2147549700 Timestamp "Time in millis";
CM_ SG_ 2147614977 Debug "Essentially a print statement up to 64 bytes long that whichever targeted can parse";
CM_ SG_ 2147615233 Timestamp "Time in millis";
CM_ SG_ 2147626500 BSPD_Signal "4-20 mA signal";
CM_ SG_ 2147626500 BSE_Signal "4-20 mA signal";
CM_ SG_ 2147626500 APPS_1_Signal "4-20 mA signal";
CM_ SG_ 2147626500 APPS_2_Signal "4-20 mA signal";
CM_ SG_ 2147626500 Brakeline_F_Signal "4-20 mA signal";
CM_ SG_ 2147626500 Brakeline_R_Signal "4-20 mA signal";
CM_ SG_ 2147626500 Steering_Angle_Signal "4-20 mA signal";
CM_ SG_ 2147626500 AUX_Signal "4-20 mA signal";
CM_ SG_ 2147626756 Elapsed_Cycles "Represents the total number of clock cycles elapsed for 10 iterations of the main loop";
CM_ SG_ 2147615264 Timestamp "Time in millis";
CM_ SG_ 2147615265 Timestamp "Time in millis";
CM_ SG_ 2147615266 Timestamp "Time in millis";
CM_ SG_ 2147615267 Timestamp "Time in millis";
CM_ SG_ 2147615268 Timestamp "Time in millis";
CM_ SG_ 2147615269 Timestamp "Time in millis";
CM_ SG_ 2147615270 Timestamp "Time in millis";
CM_ SG_ 2147615271 Timestamp "Time in millis";
CM_ SG_ 2147746305 Timestamp "Time in millis";
CM_ SG_ 2150642436 ALT "altitude";
CM_ SG_ 2150641924 LAT "lattitude";
CM_ SG_ 2150642180 LON "longitude";
CM_ SG_ 2150641668 DGPS_U "U";
CM_ SG_ 2150641668 DGPS_V "V";
CM_ SG_ 2150641668 DGPS_W "W";
CM_ SG_ 514 Timestamp "Time in millis";
CM_ SG_ 2150105602 Timestamp "Time in millis";
CM_ SG_ 2150171138 Timestamp "Time in millis";
CM_ SG_ 2150236674 Timestamp "Time in millis";
CM_ SG_ 2150302210 Timestamp "Time in millis";
BO_ 2181038594 SAMM_Mag_1_Ping_to_ECU: 4 SAMM_Mag_1
 SG_ Timestamp : 0|32@1+ (1,0) [0|4.29497e+09] "ms" ECU

BO_ 2182087170 SAMM_Mag_2_Ping_to_ECU: 4 SAMM_Mag_2
 SG_ Timestamp : 0|32@1+ (1,0) [0|4.29497e+09] "ms" ECU

BO_ 2183135746 SAMM_ToF_1_Ping_to_ECU: 4 SAMM_ToF_1
 SG_ Timestamp : 0|32@1+ (1,0) [0|4.29497e+09] "ms" ECU

BO_ 2184184322 SAMM_ToF_2_Ping_to_ECU: 4 SAMM_ToF_2
 SG_ Timestamp : 0|32@1+ (1,0) [0|4.29497e+09] "ms" ECU

BO_ 2185232898 TireTemp_FL_Ping_to_ECU: 4 TireTemp_FL
 SG_ Timestamp : 0|32@1+ (1,0) [0|4.29497e+09] "ms" ECU

BO_ 2186281474 TireTemp_FR_Ping_to_ECU: 4 TireTemp_FR
 SG_ Timestamp : 0|32@1+ (1,0) [0|4.29497e+09] "ms" ECU

BO_ 2187330050 TireTemp_RL_Ping_to_ECU: 4 TireTemp_RL
 SG_ Timestamp : 0|32@1+ (1,0) [0|4.29497e+09] "ms" ECU

BO_ 2188378626 TireTemp_RR_Ping_to_ECU: 4 TireTemp_RR
 SG_ Timestamp : 0|32@1+ (1,0) [0|4.29497e+09] "ms" ECU

CM_ SG_ 2150629633 Debug "Essentially a print statement up to 64 bytes long that whichever targeted can parse";
CM_ SG_ 2150629889 Timestamp "Time in millis";
CM_ SG_ 2150629890 Timestamp "Time in millis";
CM_ SG_ 2150632706 Cell_0_Voltage "Cell  n voltage";
CM_ SG_ 2150632706 Cell_0_Temp "Cell n temperature";
CM_ SG_ 2150632706 Cell_1_Voltage "Cell  n voltage";
CM_ SG_ 2150632706 Cell_1_Temp "Cell n temperature";
CM_ SG_ 2150632706 Cell_2_Voltage "Cell  n voltage";
CM_ SG_ 2150632706 Cell_2_Temp "Cell n temperature";
CM_ SG_ 2150632706 Cell_3_Voltage "Cell  n voltage";
CM_ SG_ 2150632706 Cell_3_Temp "Cell n temperature";
CM_ SG_ 2150632706 Cell_4_Voltage "Cell  n voltage";
CM_ SG_ 2150632706 Cell_4_Temp "Cell n temperature";
CM_ SG_ 2150632706 Cell_5_Voltage "Cell  n voltage";
CM_ SG_ 2150632706 Cell_5_Temp "Cell n temperature";
CM_ SG_ 2150632706 Cell_6_Voltage "Cell  n voltage";
CM_ SG_ 2150632706 Cell_6_Temp "Cell n temperature";
CM_ SG_ 2150632706 Cell_7_Voltage "Cell  n voltage";
CM_ SG_ 2150632706 Cell_7_Temp "Cell n temperature";
CM_ SG_ 2150632706 Cell_8_Voltage "Cell  n voltage";
CM_ SG_ 2150632706 Cell_8_Temp "Cell n temperature";
CM_ SG_ 2150632706 Cell_9_Voltage "Cell  n voltage";
CM_ SG_ 2150632706 Cell_9_Temp "Cell n temperature";
CM_ SG_ 2150632706 Cell_10_Voltage "Cell  n voltage";
CM_ SG_ 2150632706 Cell_10_Temp "Cell n temperature";
CM_ SG_ 2150632706 Cell_11_Voltage "Cell  n voltage";
CM_ SG_ 2150632706 Cell_11_Temp "Cell n temperature";
CM_ SG_ 2150632706 Cell_12_Voltage "Cell  n voltage";
CM_ SG_ 2150632706 Cell_12_Temp "Cell n temperature";
CM_ SG_ 2150632706 Cell_13_Voltage "Cell  n voltage";
CM_ SG_ 2150632706 Cell_13_Temp "Cell n temperature";
CM_ SG_ 2150632706 Cell_14_Voltage "Cell  n voltage";
CM_ SG_ 2150632706 Cell_14_Temp "Cell n temperature";
CM_ SG_ 2150632706 Cell_15_Voltage "Cell  n voltage";
CM_ SG_ 2150632706 Cell_15_Temp "Cell n temperature";
CM_ SG_ 2150632706 Cell_16_Voltage "Cell  n voltage";
CM_ SG_ 2150632706 Cell_16_Temp "Cell n temperature";
CM_ SG_ 2150632706 Cell_17_Voltage "Cell  n voltage";
CM_ SG_ 2150632706 Cell_17_Temp "Cell n temperature";
CM_ SG_ 2150632706 Cell_18_Voltage "Cell  n voltage";
CM_ SG_ 2150632706 Cell_18_Temp "Cell n temperature";
CM_ SG_ 2150632706 Cell_19_Voltage "Cell  n voltage";
CM_ SG_ 2150632706 Cell_19_Temp "Cell n temperature";
CM_ SG_ 2150632706 Cell_20_Voltage "Cell  n voltage";
CM_ SG_ 2150632706 Cell_20_Temp "Cell n temperature";
CM_ SG_ 2150632706 Cell_21_Voltage "Cell  n voltage";
CM_ SG_ 2150632706 Cell_21_Temp "Cell n temperature";
CM_ SG_ 2150632706 Cell_22_Voltage "Cell  n voltage";
CM_ SG_ 2150632706 Cell_22_Temp "Cell n temperature";
CM_ SG_ 2150632706 Cell_23_Voltage "Cell  n voltage";
CM_ SG_ 2150632706 Cell_23_Temp "Cell n temperature";
CM_ SG_ 2150632706 Cell_24_Voltage "Cell  n voltage";
CM_ SG_ 2150632706 Cell_24_Temp "Cell n temperature";
CM_ SG_ 2150632706 Cell_25_Voltage "Cell  n voltage";
CM_ SG_ 2150632706 Cell_25_Temp "Cell n temperature";
CM_ SG_ 2150632706 Cell_26_Voltage "Cell  n voltage";
CM_ SG_ 2150632706 Cell_26_Temp "Cell n temperature";
CM_ SG_ 2150632706 Cell_27_Voltage "Cell  n voltage";
CM_ SG_ 2150632706 Cell_27_Temp "Cell n temperature";
CM_ SG_ 2150632706 Cell_28_Voltage "Cell  n voltage";
CM_ SG_ 2150632706 Cell_28_Temp "Cell n temperature";
CM_ SG_ 2150632706 Cell_29_Voltage "Cell  n voltage";
CM_ SG_ 2150632706 Cell_29_Temp "Cell n temperature";
CM_ SG_ 2150632706 Cell_30_Voltage "Cell  n voltage";
CM_ SG_ 2150632706 Cell_30_Temp "Cell n temperature";
CM_ SG_ 2150632706 Cell_31_Voltage "Cell  n voltage";
CM_ SG_ 2150632706 Cell_31_Temp "Cell n temperature";
CM_ SG_ 2150632962 Cell_32_Voltage "Cell  n voltage";
CM_ SG_ 2150632962 Cell_32_Temp "Cell n temperature";
CM_ SG_ 2150632962 Cell_33_Voltage "Cell  n voltage";
CM_ SG_ 2150632962 Cell_33_Temp "Cell n temperature";
CM_ SG_ 2150632962 Cell_34_Voltage "Cell  n voltage";
CM_ SG_ 2150632962 Cell_34_Temp "Cell n temperature";
CM_ SG_ 2150632962 Cell_35_Voltage "Cell  n voltage";
CM_ SG_ 2150632962 Cell_35_Temp "Cell n temperature";
CM_ SG_ 2150632962 Cell_36_Voltage "Cell  n voltage";
CM_ SG_ 2150632962 Cell_36_Temp "Cell n temperature";
CM_ SG_ 2150632962 Cell_37_Voltage "Cell  n voltage";
CM_ SG_ 2150632962 Cell_37_Temp "Cell n temperature";
CM_ SG_ 2150632962 Cell_38_Voltage "Cell  n voltage";
CM_ SG_ 2150632962 Cell_38_Temp "Cell n temperature";
CM_ SG_ 2150632962 Cell_39_Voltage "Cell  n voltage";
CM_ SG_ 2150632962 Cell_39_Temp "Cell n temperature";
CM_ SG_ 2150632962 Cell_40_Voltage "Cell  n voltage";
CM_ SG_ 2150632962 Cell_40_Temp "Cell n temperature";
CM_ SG_ 2150632962 Cell_41_Voltage "Cell  n voltage";
CM_ SG_ 2150632962 Cell_41_Temp "Cell n temperature";
CM_ SG_ 2150632962 Cell_42_Voltage "Cell  n voltage";
CM_ SG_ 2150632962 Cell_42_Temp "Cell n temperature";
CM_ SG_ 2150632962 Cell_43_Voltage "Cell  n voltage";
CM_ SG_ 2150632962 Cell_43_Temp "Cell n temperature";
CM_ SG_ 2150632962 Cell_44_Voltage "Cell  n voltage";
CM_ SG_ 2150632962 Cell_44_Temp "Cell n temperature";
CM_ SG_ 2150632962 Cell_45_Voltage "Cell  n voltage";
CM_ SG_ 2150632962 Cell_45_Temp "Cell n temperature";
CM_ SG_ 2150632962 Cell_46_Voltage "Cell  n voltage";
CM_ SG_ 2150632962 Cell_46_Temp "Cell n temperature";
CM_ SG_ 2150632962 Cell_47_Voltage "Cell  n voltage";
CM_ SG_ 2150632962 Cell_47_Temp "Cell n temperature";
CM_ SG_ 2150632962 Cell_48_Voltage "Cell  n voltage";
CM_ SG_ 2150632962 Cell_48_Temp "Cell n temperature";
CM_ SG_ 2150632962 Cell_49_Voltage "Cell  n voltage";
CM_ SG_ 2150632962 Cell_49_Temp "Cell n temperature";
CM_ SG_ 2150632962 Cell_50_Voltage "Cell  n voltage";
CM_ SG_ 2150632962 Cell_50_Temp "Cell n temperature";
CM_ SG_ 2150632962 Cell_51_Voltage "Cell  n voltage";
CM_ SG_ 2150632962 Cell_51_Temp "Cell n temperature";
CM_ SG_ 2150632962 Cell_52_Voltage "Cell  n voltage";
CM_ SG_ 2150632962 Cell_52_Temp "Cell n temperature";
CM_ SG_ 2150632962 Cell_53_Voltage "Cell  n voltage";
CM_ SG_ 2150632962 Cell_53_Temp "Cell n temperature";
CM_ SG_ 2150632962 Cell_54_Voltage "Cell  n voltage";
CM_ SG_ 2150632962 Cell_54_Temp "Cell n temperature";
CM_ SG_ 2150632962 Cell_55_Voltage "Cell  n voltage";
CM_ SG_ 2150632962 Cell_55_Temp "Cell n temperature";
CM_ SG_ 2150632962 Cell_56_Voltage "Cell  n voltage";
CM_ SG_ 2150632962 Cell_56_Temp "Cell n temperature";
CM_ SG_ 2150632962 Cell_57_Voltage "Cell  n voltage";
CM_ SG_ 2150632962 Cell_57_Temp "Cell n temperature";
CM_ SG_ 2150632962 Cell_58_Voltage "Cell  n voltage";
CM_ SG_ 2150632962 Cell_58_Temp "Cell n temperature";
CM_ SG_ 2150632962 Cell_59_Voltage "Cell  n voltage";
CM_ SG_ 2150632962 Cell_59_Temp "Cell n temperature";
CM_ SG_ 2150632962 Cell_60_Voltage "Cell  n voltage";
CM_ SG_ 2150632962 Cell_60_Temp "Cell n temperature";
CM_ SG_ 2150632962 Cell_61_Voltage "Cell  n voltage";
CM_ SG_ 2150632962 Cell_61_Temp "Cell n temperature";
CM_ SG_ 2150632962 Cell_62_Voltage "Cell  n voltage";
CM_ SG_ 2150632962 Cell_62_Temp "Cell n temperature";
CM_ SG_ 2150632962 Cell_63_Voltage "Cell  n voltage";
CM_ SG_ 2150632962 Cell_63_Temp "Cell n temperature";
CM_ SG_ 2150633218 Cell_64_Voltage "Cell  n voltage";
CM_ SG_ 2150633218 Cell_64_Temp "Cell n temperature";
CM_ SG_ 2150633218 Cell_65_Voltage "Cell  n voltage";
CM_ SG_ 2150633218 Cell_65_Temp "Cell n temperature";
CM_ SG_ 2150633218 Cell_66_Voltage "Cell  n voltage";
CM_ SG_ 2150633218 Cell_66_Temp "Cell n temperature";
CM_ SG_ 2150633218 Cell_67_Voltage "Cell  n voltage";
CM_ SG_ 2150633218 Cell_67_Temp "Cell n temperature";
CM_ SG_ 2150633218 Cell_68_Voltage "Cell  n voltage";
CM_ SG_ 2150633218 Cell_68_Temp "Cell n temperature";
CM_ SG_ 2150633218 Cell_69_Voltage "Cell  n voltage";
CM_ SG_ 2150633218 Cell_69_Temp "Cell n temperature";
CM_ SG_ 2150633218 Cell_70_Voltage "Cell  n voltage";
CM_ SG_ 2150633218 Cell_70_Temp "Cell n temperature";
CM_ SG_ 2150633218 Cell_71_Voltage "Cell  n voltage";
CM_ SG_ 2150633218 Cell_71_Temp "Cell n temperature";
CM_ SG_ 2150633218 Cell_72_Voltage "Cell  n voltage";
CM_ SG_ 2150633218 Cell_72_Temp "Cell n temperature";
CM_ SG_ 2150633218 Cell_73_Voltage "Cell  n voltage";
CM_ SG_ 2150633218 Cell_73_Temp "Cell n temperature";
CM_ SG_ 2150633218 Cell_74_Voltage "Cell  n voltage";
CM_ SG_ 2150633218 Cell_74_Temp "Cell n temperature";
CM_ SG_ 2150633218 Cell_75_Voltage "Cell  n voltage";
CM_ SG_ 2150633218 Cell_75_Temp "Cell n temperature";
CM_ SG_ 2150633218 Cell_76_Voltage "Cell  n voltage";
CM_ SG_ 2150633218 Cell_76_Temp "Cell n temperature";
CM_ SG_ 2150633218 Cell_77_Voltage "Cell  n voltage";
CM_ SG_ 2150633218 Cell_77_Temp "Cell n temperature";
CM_ SG_ 2150633218 Cell_78_Voltage "Cell  n voltage";
CM_ SG_ 2150633218 Cell_78_Temp "Cell n temperature";
CM_ SG_ 2150633218 Cell_79_Voltage "Cell  n voltage";
CM_ SG_ 2150633218 Cell_79_Temp "Cell n temperature";
CM_ SG_ 2150633218 Cell_80_Voltage "Cell  n voltage";
CM_ SG_ 2150633218 Cell_80_Temp "Cell n temperature";
CM_ SG_ 2150633218 Cell_81_Voltage "Cell  n voltage";
CM_ SG_ 2150633218 Cell_81_Temp "Cell n temperature";
CM_ SG_ 2150633218 Cell_82_Voltage "Cell  n voltage";
CM_ SG_ 2150633218 Cell_82_Temp "Cell n temperature";
CM_ SG_ 2150633218 Cell_83_Voltage "Cell  n voltage";
CM_ SG_ 2150633218 Cell_83_Temp "Cell n temperature";
CM_ SG_ 2150633218 Cell_84_Voltage "Cell  n voltage";
CM_ SG_ 2150633218 Cell_84_Temp "Cell n temperature";
CM_ SG_ 2150633218 Cell_85_Voltage "Cell  n voltage";
CM_ SG_ 2150633218 Cell_85_Temp "Cell n temperature";
CM_ SG_ 2150633218 Cell_86_Voltage "Cell  n voltage";
CM_ SG_ 2150633218 Cell_86_Temp "Cell n temperature";
CM_ SG_ 2150633218 Cell_87_Voltage "Cell  n voltage";
CM_ SG_ 2150633218 Cell_87_Temp "Cell n temperature";
CM_ SG_ 2150633218 Cell_88_Voltage "Cell  n voltage";
CM_ SG_ 2150633218 Cell_88_Temp "Cell n temperature";
CM_ SG_ 2150633218 Cell_89_Voltage "Cell  n voltage";
CM_ SG_ 2150633218 Cell_89_Temp "Cell n temperature";
CM_ SG_ 2150633218 Cell_90_Voltage "Cell  n voltage";
CM_ SG_ 2150633218 Cell_90_Temp "Cell n temperature";
CM_ SG_ 2150633218 Cell_91_Voltage "Cell  n voltage";
CM_ SG_ 2150633218 Cell_91_Temp "Cell n temperature";
CM_ SG_ 2150633218 Cell_92_Voltage "Cell  n voltage";
CM_ SG_ 2150633218 Cell_92_Temp "Cell n temperature";
CM_ SG_ 2150633218 Cell_93_Voltage "Cell  n voltage";
CM_ SG_ 2150633218 Cell_93_Temp "Cell n temperature";
CM_ SG_ 2150633218 Cell_94_Voltage "Cell  n voltage";
CM_ SG_ 2150633218 Cell_94_Temp "Cell n temperature";
CM_ SG_ 2150633218 Cell_95_Voltage "Cell  n voltage";
CM_ SG_ 2150633218 Cell_95_Temp "Cell n temperature";
CM_ SG_ 2150633474 Cell_96_Voltage "Cell  n voltage";
CM_ SG_ 2150633474 Cell_96_Temp "Cell n temperature";
CM_ SG_ 2150633474 Cell_97_Voltage "Cell  n voltage";
CM_ SG_ 2150633474 Cell_97_Temp "Cell n temperature";
CM_ SG_ 2150633474 Cell_98_Voltage "Cell  n voltage";
CM_ SG_ 2150633474 Cell_98_Temp "Cell n temperature";
CM_ SG_ 2150633474 Cell_99_Voltage "Cell  n voltage";
CM_ SG_ 2150633474 Cell_99_Temp "Cell n temperature";
CM_ SG_ 2150633474 Cell_100_Voltage "Cell  n voltage";
CM_ SG_ 2150633474 Cell_100_Temp "Cell n temperature";
CM_ SG_ 2150633474 Cell_101_Voltage "Cell  n voltage";
CM_ SG_ 2150633474 Cell_101_Temp "Cell n temperature";
CM_ SG_ 2150633474 Cell_102_Voltage "Cell  n voltage";
CM_ SG_ 2150633474 Cell_102_Temp "Cell n temperature";
CM_ SG_ 2150633474 Cell_103_Voltage "Cell  n voltage";
CM_ SG_ 2150633474 Cell_103_Temp "Cell n temperature";
CM_ SG_ 2150633474 Cell_104_Voltage "Cell  n voltage";
CM_ SG_ 2150633474 Cell_104_Temp "Cell n temperature";
CM_ SG_ 2150633474 Cell_105_Voltage "Cell  n voltage";
CM_ SG_ 2150633474 Cell_105_Temp "Cell n temperature";
CM_ SG_ 2150633474 Cell_106_Voltage "Cell  n voltage";
CM_ SG_ 2150633474 Cell_106_Temp "Cell n temperature";
CM_ SG_ 2150633474 Cell_107_Voltage "Cell  n voltage";
CM_ SG_ 2150633474 Cell_107_Temp "Cell n temperature";
CM_ SG_ 2150633474 Cell_108_Voltage "Cell  n voltage";
CM_ SG_ 2150633474 Cell_108_Temp "Cell n temperature";
CM_ SG_ 2150633474 Cell_109_Voltage "Cell  n voltage";
CM_ SG_ 2150633474 Cell_109_Temp "Cell n temperature";
CM_ SG_ 2150633474 Cell_110_Voltage "Cell  n voltage";
CM_ SG_ 2150633474 Cell_110_Temp "Cell n temperature";
CM_ SG_ 2150633474 Cell_111_Voltage "Cell  n voltage";
CM_ SG_ 2150633474 Cell_111_Temp "Cell n temperature";
CM_ SG_ 2150633474 Cell_112_Voltage "Cell  n voltage";
CM_ SG_ 2150633474 Cell_112_Temp "Cell n temperature";
CM_ SG_ 2150633474 Cell_113_Voltage "Cell  n voltage";
CM_ SG_ 2150633474 Cell_113_Temp "Cell n temperature";
CM_ SG_ 2150633474 Cell_114_Voltage "Cell  n voltage";
CM_ SG_ 2150633474 Cell_114_Temp "Cell n temperature";
CM_ SG_ 2150633474 Cell_115_Voltage "Cell  n voltage";
CM_ SG_ 2150633474 Cell_115_Temp "Cell n temperature";
CM_ SG_ 2150633474 Cell_116_Voltage "Cell  n voltage";
CM_ SG_ 2150633474 Cell_116_Temp "Cell n temperature";
CM_ SG_ 2150633474 Cell_117_Voltage "Cell  n voltage";
CM_ SG_ 2150633474 Cell_117_Temp "Cell n temperature";
CM_ SG_ 2150633474 Cell_118_Voltage "Cell  n voltage";
CM_ SG_ 2150633474 Cell_118_Temp "Cell n temperature";
CM_ SG_ 2150633474 Cell_119_Voltage "Cell  n voltage";
CM_ SG_ 2150633474 Cell_119_Temp "Cell n temperature";
CM_ SG_ 2150633474 Cell_120_Voltage "Cell  n voltage";
CM_ SG_ 2150633474 Cell_120_Temp "Cell n temperature";
CM_ SG_ 2150633474 Cell_121_Voltage "Cell  n voltage";
CM_ SG_ 2150633474 Cell_121_Temp "Cell n temperature";
CM_ SG_ 2150633474 Cell_122_Voltage "Cell  n voltage";
CM_ SG_ 2150633474 Cell_122_Temp "Cell n temperature";
CM_ SG_ 2150633474 Cell_123_Voltage "Cell  n voltage";
CM_ SG_ 2150633474 Cell_123_Temp "Cell n temperature";
CM_ SG_ 2150633474 Cell_124_Voltage "Cell  n voltage";
CM_ SG_ 2150633474 Cell_124_Temp "Cell n temperature";
CM_ SG_ 2150633474 Cell_125_Voltage "Cell  n voltage";
CM_ SG_ 2150633474 Cell_125_Temp "Cell n temperature";
CM_ SG_ 2150633474 Cell_126_Voltage "Cell  n voltage";
CM_ SG_ 2150633474 Cell_126_Temp "Cell n temperature";
CM_ SG_ 2150633474 Cell_127_Voltage "Cell  n voltage";
CM_ SG_ 2150633474 Cell_127_Temp "Cell n temperature";
CM_ SG_ 2150633730 Cell_128_Voltage "Cell  n voltage";
CM_ SG_ 2150633730 Cell_128_Temp "Cell n temperature";
CM_ SG_ 2150633730 Cell_129_Voltage "Cell  n voltage";
CM_ SG_ 2150633730 Cell_129_Temp "Cell n temperature";
CM_ SG_ 2150633730 Cell_130_Voltage "Cell  n voltage";
CM_ SG_ 2150633730 Cell_130_Temp "Cell n temperature";
CM_ SG_ 2150633730 Cell_131_Voltage "Cell  n voltage";
CM_ SG_ 2150633730 Cell_131_Temp "Cell n temperature";
CM_ SG_ 2150633730 Cell_132_Voltage "Cell  n voltage";
CM_ SG_ 2150633730 Cell_132_Temp "Cell n temperature";
CM_ SG_ 2150633730 Cell_133_Voltage "Cell  n voltage";
CM_ SG_ 2150633730 Cell_133_Temp "Cell n temperature";
CM_ SG_ 2150633730 Cell_134_Voltage "Cell  n voltage";
CM_ SG_ 2150633730 Cell_134_Temp "Cell n temperature";
CM_ SG_ 2150633730 Cell_135_Voltage "Cell  n voltage";
CM_ SG_ 2150633730 Cell_135_Temp "Cell n temperature";
CM_ SG_ 2150633730 Cell_136_Voltage "Cell  n voltage";
CM_ SG_ 2150633730 Cell_136_Temp "Cell n temperature";
CM_ SG_ 2150633730 Cell_137_Voltage "Cell  n voltage";
CM_ SG_ 2150633730 Cell_137_Temp "Cell n temperature";
CM_ SG_ 2150633730 Cell_138_Voltage "Cell  n voltage";
CM_ SG_ 2150633730 Cell_138_Temp "Cell n temperature";
CM_ SG_ 2150633730 Cell_139_Voltage "Cell  n voltage";
CM_ SG_ 2150633730 Cell_139_Temp "Cell n temperature";
CM_ SG_ 2150633730 Cell_140_Voltage "Cell  n voltage";
CM_ SG_ 2150633730 Cell_140_Temp "Cell n temperature";
CM_ SG_ 2150633730 Cell_141_Voltage "Cell  n voltage";
CM_ SG_ 2150633730 Cell_141_Temp "Cell n temperature";
CM_ SG_ 2150633730 Cell_142_Voltage "Cell  n voltage";
CM_ SG_ 2150633730 Cell_142_Temp "Cell n temperature";
CM_ SG_ 2150633730 Cell_143_Voltage "Cell  n voltage";
CM_ SG_ 2150633730 Cell_143_Temp "Cell n temperature";
CM_ SG_ 2150633730 Cell_144_Voltage "Cell  n voltage";
CM_ SG_ 2150633730 Cell_144_Temp "Cell n temperature";
CM_ SG_ 2150633730 Cell_145_Voltage "Cell  n voltage";
CM_ SG_ 2150633730 Cell_145_Temp "Cell n temperature";
CM_ SG_ 2150633730 Cell_146_Voltage "Cell  n voltage";
CM_ SG_ 2150633730 Cell_146_Temp "Cell n temperature";
CM_ SG_ 2150633730 Cell_147_Voltage "Cell  n voltage";
CM_ SG_ 2150633730 Cell_147_Temp "Cell n temperature";
CM_ SG_ 2150633730 Cell_148_Voltage "Cell  n voltage";
CM_ SG_ 2150633730 Cell_148_Temp "Cell n temperature";
CM_ SG_ 2150633730 Cell_149_Voltage "Cell  n voltage";
CM_ SG_ 2150633730 Cell_149_Temp "Cell n temperature";
CM_ SG_ 2150633730 Cell_150_Voltage "Cell  n voltage";
CM_ SG_ 2150633730 Cell_150_Temp "Cell n temperature";
CM_ SG_ 2150633730 Cell_151_Voltage "Cell  n voltage";
CM_ SG_ 2150633730 Cell_151_Temp "Cell n temperature";
CM_ SG_ 2150633730 Cell_152_Voltage "Cell  n voltage";
CM_ SG_ 2150633730 Cell_152_Temp "Cell n temperature";
CM_ SG_ 2150633730 Cell_153_Voltage "Cell  n voltage";
CM_ SG_ 2150633730 Cell_153_Temp "Cell n temperature";
CM_ SG_ 2150633730 Cell_154_Voltage "Cell  n voltage";
CM_ SG_ 2150633730 Cell_154_Temp "Cell n temperature";
CM_ SG_ 2150633730 Cell_155_Voltage "Cell  n voltage";
CM_ SG_ 2150633730 Cell_155_Temp "Cell n temperature";
CM_ SG_ 2150633730 Cell_156_Voltage "Cell  n voltage";
CM_ SG_ 2150633730 Cell_156_Temp "Cell n temperature";
CM_ SG_ 2150633730 Cell_157_Voltage "Cell  n voltage";
CM_ SG_ 2150633730 Cell_157_Temp "Cell n temperature";
CM_ SG_ 2150633730 Cell_158_Voltage "Cell  n voltage";
CM_ SG_ 2150633730 Cell_158_Temp "Cell n temperature";
CM_ SG_ 2150633730 Cell_159_Voltage "Cell  n voltage";
CM_ SG_ 2150633730 Cell_159_Temp "Cell n temperature";
CM_ SG_ 2148532482 Debug "Essentially a print statement up to 64 bytes long that whichever targeted can parse";
CM_ SG_ 2148532738 Timestamp "Time in millis";
CM_ SG_ 2148532483 Debug "Essentially a print statement up to 64 bytes long that whichever targeted can parse";
CM_ SG_ 2148532739 Timestamp "Time in millis";
CM_ SG_ 2148532484 Debug "Essentially a print statement up to 64 bytes long that whichever targeted can parse";
CM_ SG_ 2148532740 Timestamp "Time in millis";
CM_ SG_ 2149581057 Debug "Essentially a print statement up to 64 bytes long that whichever targeted can parse";
CM_ SG_ 2149581313 Timestamp "Time in millis";
CM_ SG_ 2149592580 BSPD_Signal "4-20 mA signal";
CM_ SG_ 2149592580 BSE_Signal "4-20 mA signal";
CM_ SG_ 2149592580 APPS_1_Signal "4-20 mA signal";
CM_ SG_ 2149592580 APPS_2_Signal "4-20 mA signal";
CM_ SG_ 2149592580 Brakeline_F_Signal "4-20 mA signal";
CM_ SG_ 2149592580 Brakeline_R_Signal "4-20 mA signal";
CM_ SG_ 2149592580 Steering_Angle_Signal "4-20 mA signal";
CM_ SG_ 2149592580 AUX_Signal "4-20 mA signal";
CM_ SG_ 2149592836 Elapsed_Cycles "Represents the total number of clock cycles elapsed for 10 iterations of the main loop";
CM_ SG_ 2149581344 Timestamp "Time in millis";
CM_ SG_ 2149581345 Timestamp "Time in millis";
CM_ SG_ 2149581346 Timestamp "Time in millis";
CM_ SG_ 2149581347 Timestamp "Time in millis";
CM_ SG_ 2149581348 Timestamp "Time in millis";
CM_ SG_ 2149581349 Timestamp "Time in millis";
CM_ SG_ 2149581350 Timestamp "Time in millis";
CM_ SG_ 2149581351 Timestamp "Time in millis";
CM_ SG_ 2151678465 Timestamp "Time in millis";
CM_ SG_ 2197828356 ALT "altitude";
CM_ SG_ 2197827844 LAT "lattitude";
CM_ SG_ 2197828100 LON "longitude";
CM_ SG_ 2197827588 DGPS_U "U";
CM_ SG_ 2197827588 DGPS_V "V";
CM_ SG_ 2197827588 DGPS_W "W";
CM_ SG_ 2181038594 Timestamp "Time in millis";
CM_ SG_ 2182087170 Timestamp "Time in millis";
CM_ SG_ 2183135746 Timestamp "Time in millis";
CM_ SG_ 2184184322 Timestamp "Time in millis";
CM_ SG_ 2185232898 Timestamp "Time in millis";
CM_ SG_ 2186281474 Timestamp "Time in millis";
CM_ SG_ 2187330050 Timestamp "Time in millis";
CM_ SG_ 2188378626 Timestamp "Time in millis";
